VERSION ""

NS_ :

BS_:

BU_: XXX

BO_ 769 TeslaRadarSguInfo: 8 XXX
 SG_ RADC_VerticalMisalignment : 0|8@1+ (1,0) [0|255] "" XXX
 SG_ RADC_SCUTemperature : 8|8@1+ (1,-128) [-128|127] "" XXX
 SG_ RADC_VMA_Plaus : 16|8@1+ (1,0) [0|255] "" XXX
 SG_ RADC_SGU_ITC : 24|8@1+ (1,0) [0|255] "" XXX
 SG_ RADC_HorizontMisalignment : 32|12@1+ (1,0) [0|4096] "" XXX
 SG_ RADC_SensorDirty : 44|1@1+ (1,0) [0|1] "" XXX
 SG_ RADC_HWFail : 45|1@1+ (1,0) [0|1] "" XXX
 SG_ RADC_SGUFail : 46|1@1+ (1,0) [0|1] "" XXX
 SG_ RADC_SGUInfoConsistBit : 47|1@1+ (1,0) [0|1] "" XXX

BO_ 770 TeslaRadarTguInfo: 8 XXX
 SG_ RADC_ACCTargObj1_sguIndex : 0|6@1+ (1,0) [0|63] "" XXX
 SG_ RADC_ACCTargObj2_sguIndex : 6|6@1+ (1,0) [0|63] "" XXX
 SG_ RADC_ACCTargObj3_sguIndex : 12|6@1+ (1,0) [0|63] "" XXX
 SG_ RADC_ACCTargObj4_sguIndex : 18|6@1+ (1,0) [0|63] "" XXX
 SG_ RADC_ACCTargObj5_sguIndex : 24|6@1+ (1,0) [0|63] "" XXX
 SG_ unused30 : 30|1@1+ (1,0) [0|1] "" XXX
 SG_ RADC_TGUInfoConsistBit : 31|1@1+ (1,0) [0|1] "" XXX
 SG_ RADC_ACCTargObj1_dBPower : 32|16@1+ (1,0) [0|65535] "" XXX
 SG_ RADC_ACCTargObj5_dBPower : 48|16@1+ (1,0) [0|65535] "" XXX

BO_ 1281 TeslaRadarAlertMatrix: 8 XXX
 SG_ RADC_a001_ecuInternalPerf : 0|1@1+ (1,0) [0|1] "" XXX
 SG_ RADC_a002_flashPerformance : 1|1@1+ (1,0) [0|1] "" XXX
 SG_ RADC_a003_vBatHigh : 2|1@1+ (1,0) [0|1] "" XXX
 SG_ RADC_a004_adjustmentNotDone : 3|1@1+ (1,0) [0|1] "" XXX
 SG_ RADC_a005_adjustmentReq : 4|1@1+ (1,0) [0|1] "" XXX
 SG_ RADC_a006_adjustmentNotOk : 5|1@1+ (1,0) [0|1] "" XXX
 SG_ RADC_a007_sensorBlinded : 6|1@1+ (1,0) [0|1] "" XXX
 SG_ RADC_a008_plantModeActive : 7|1@1+ (1,0) [0|1] "" XXX
 SG_ RADC_a009_configMismatch : 8|1@1+ (1,0) [0|1] "" XXX
 SG_ RADC_a010_canBusOff : 9|1@1+ (1,0) [0|1] "" XXX
 SG_ RADC_a011_bdyMIA : 10|1@1+ (1,0) [0|1] "" XXX
 SG_ RADC_a012_espMIA : 11|1@1+ (1,0) [0|1] "" XXX
 SG_ RADC_a013_gtwMIA : 12|1@1+ (1,0) [0|1] "" XXX
 SG_ RADC_a014_sccmMIA : 13|1@1+ (1,0) [0|1] "" XXX
 SG_ RADC_a015_adasMIA : 14|1@1+ (1,0) [0|1] "" XXX
 SG_ RADC_a016_bdyInvalidCount : 15|1@1+ (1,0) [0|1] "" XXX
 SG_ RADC_a017_adasInvalidCount : 16|1@1+ (1,0) [0|1] "" XXX
 SG_ RADC_a018_espInvalidCount : 17|1@1+ (1,0) [0|1] "" XXX
 SG_ RADC_a019_sccmInvalidCount : 18|1@1+ (1,0) [0|1] "" XXX
 SG_ RADC_a020_bdyInvalidChkSm : 19|1@1+ (1,0) [0|1] "" XXX
 SG_ RADC_a021_espInvalidChkSm : 20|1@1+ (1,0) [0|1] "" XXX
 SG_ RADC_a022_sccmInvalidChkSm : 21|1@1+ (1,0) [0|1] "" XXX
 SG_ RADC_a023_sccmInvalidChkSm : 22|1@1+ (1,0) [0|1] "" XXX
 SG_ RADC_a024_absValidity : 23|1@1+ (1,0) [0|1] "" XXX
 SG_ RADC_a025_ambTValidity : 24|1@1+ (1,0) [0|1] "" XXX
 SG_ RADC_a026_brakeValidity : 25|1@1+ (1,0) [0|1] "" XXX
 SG_ RADC_a027_CntryCdValidity : 26|1@1+ (1,0) [0|1] "" XXX
 SG_ RADC_a028_espValidity : 27|1@1+ (1,0) [0|1] "" XXX
 SG_ RADC_a029_longAccOffValidity : 28|1@1+ (1,0) [0|1] "" XXX
 SG_ RADC_a030_longAccValidity : 29|1@1+ (1,0) [0|1] "" XXX
 SG_ RADC_a031_odoValidity : 30|1@1+ (1,0) [0|1] "" XXX
 SG_ RADC_a032_gearValidity : 31|1@1+ (1,0) [0|1] "" XXX
 SG_ RADC_a033_steerAngValidity : 32|1@1+ (1,0) [0|1] "" XXX
 SG_ RADC_a034_steerAngSpdValidity : 33|1@1+ (1,0) [0|1] "" XXX
 SG_ RADC_a035_indctrValidity : 34|1@1+ (1,0) [0|1] "" XXX
 SG_ RADC_a036_vehStandStillValidity : 35|1@1+ (1,0) [0|1] "" XXX
 SG_ RADC_a037_vinValidity : 36|1@1+ (1,0) [0|1] "" XXX
 SG_ RADC_a038_whlRotValidity : 37|1@1+ (1,0) [0|1] "" XXX
 SG_ RADC_a039_whlSpdValidity : 38|1@1+ (1,0) [0|1] "" XXX
 SG_ RADC_a040_whlStandStillValidity : 39|1@1+ (1,0) [0|1] "" XXX
 SG_ RADC_a041_wiperValidity : 40|1@1+ (1,0) [0|1] "" XXX
 SG_ RADC_a042_xwdValidity : 41|1@1+ (1,0) [0|1] "" XXX
 SG_ RADC_a043_yawOffValidity : 42|1@1+ (1,0) [0|1] "" XXX
 SG_ RADC_a044_yawValidity : 43|1@1+ (1,0) [0|1] "" XXX
 SG_ RADC_a045_bsdSanity : 44|1@1+ (1,0) [0|1] "" XXX
 SG_ RADC_a046_rctaSanity : 45|1@1+ (1,0) [0|1] "" XXX
 SG_ RADC_a047_lcwSanity : 46|1@1+ (1,0) [0|1] "" XXX
 SG_ RADC_a048_steerAngOffSanity : 47|1@1+ (1,0) [0|1] "" XXX
 SG_ RADC_a049_tireSizeSanity : 48|1@1+ (1,0) [0|1] "" XXX
 SG_ RADC_a050_velocitySanity : 49|1@1+ (1,0) [0|1] "" XXX
 SG_ RADC_a051_yawSanity : 50|1@1+ (1,0) [0|1] "" XXX
 SG_ RADC_a052_radomeHtrInop : 51|1@1+ (1,0) [0|1] "" XXX
 SG_ RADC_a053_espmodValidity : 52|1@1+ (1,0) [0|1] "" XXX
 SG_ RADC_a054_gtwmodValidity : 53|1@1+ (1,0) [0|1] "" XXX
 SG_ RADC_a055_stwmodValidity : 54|1@1+ (1,0) [0|1] "" XXX
 SG_ RADC_a056_bcmodValidity : 55|1@1+ (1,0) [0|1] "" XXX
 SG_ RADC_a057_dimodValidity : 56|1@1+ (1,0) [0|1] "" XXX
 SG_ RADC_a058_opmodValidity : 57|1@1+ (1,0) [0|1] "" XXX
 SG_ RADC_a059_drmiInvalidChkSm : 58|1@1+ (1,0) [0|1] "" XXX
 SG_ RADC_a060_drmiInvalidCount : 59|1@1+ (1,0) [0|1] "" XXX
 SG_ RADC_a061_radPositionMismatch : 60|1@1+ (1,0) [0|1] "" XXX
 SG_ RADC_a062_strRackMismatch : 61|1@1+ (1,0) [0|1] "" XXX
 SG_ unused62 : 62|2@1+ (1,0) [0|3] "" XXX

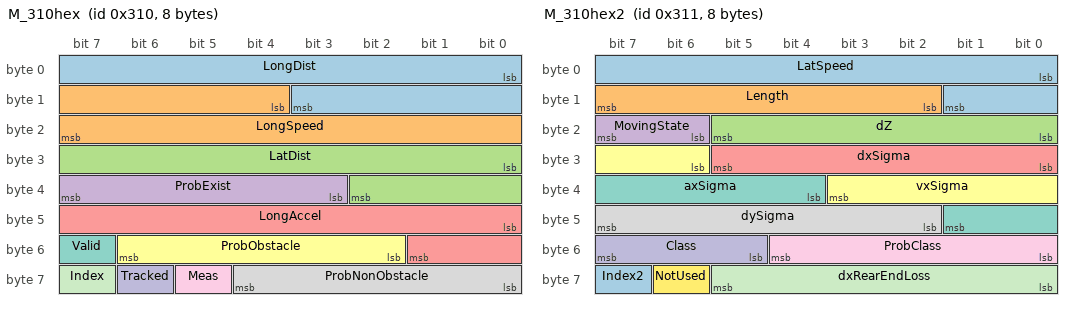
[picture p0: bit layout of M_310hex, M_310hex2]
BO_ 784 M_310hex: 8 XXX
 SG_ LongDist : 0|12@1+ (0.0625,0) [0|255.9] "meters" XXX
 SG_ LongSpeed : 12|12@1+ (0.0625,-128) [-128|128] "meters/sec" XXX
 SG_ LatDist : 24|11@1+ (0.125,-128) [-128|128] "meters" XXX
 SG_ ProbExist : 35|5@1+ (3.125,0) [0|96.875] "%" XXX
 SG_ LongAccel : 40|10@1+ (0.03125,-16) [-16|16] "meters/sec/sec" XXX
 SG_ ProbObstacle : 50|5@1+ (3.125,0) [0|96.875] "%" XXX
 SG_ Valid : 55|1@1+ (1,0) [0|1] "" XXX
 SG_ ProbNonObstacle : 56|5@1+ (3.125,0) [0|96.875] "%" XXX
 SG_ Meas : 61|1@1+ (1,0) [0|1] "" XXX
 SG_ Tracked : 62|1@1+ (1,0) [0|1] "" XXX
 SG_ Index : 63|1@1+ (1,0) [0|1] "" XXX

BO_ 785 M_310hex2: 8 XXX
 SG_ LatSpeed : 0|10@1+ (0.125,-64) [-64|64] "meters/sec" XXX
 SG_ Length : 10|6@1+ (0.125,0) [0|7.875] "m" XXX
 SG_ dZ : 16|6@1+ (0.25,-5) [-5|10.75] "m" XXX
 SG_ MovingState : 22|2@1+ (1,0) [0|3] "" XXX
 SG_ dxSigma : 24|6@1+ (1,0) [0|63] "" XXX
 SG_ vxSigma : 30|6@1+ (1,0) [0|63] "" XXX
 SG_ axSigma : 36|6@1+ (1,0) [0|63] "" XXX
 SG_ dySigma : 42|6@1+ (1,0) [0|63] "" XXX
 SG_ ProbClass : 48|5@1+ (3.125,0) [0|96.875] "%" XXX
 SG_ Class : 53|3@1+ (1,0) [0|7] "" XXX
 SG_ dxRearEndLoss : 56|6@1+ (1,0) [0|63] "" XXX
 SG_ NotUsed : 62|1@1+ (1,0) [0|1] "" XXX
 SG_ Index2 : 63|1@1+ (1,0) [0|1] "" XXX

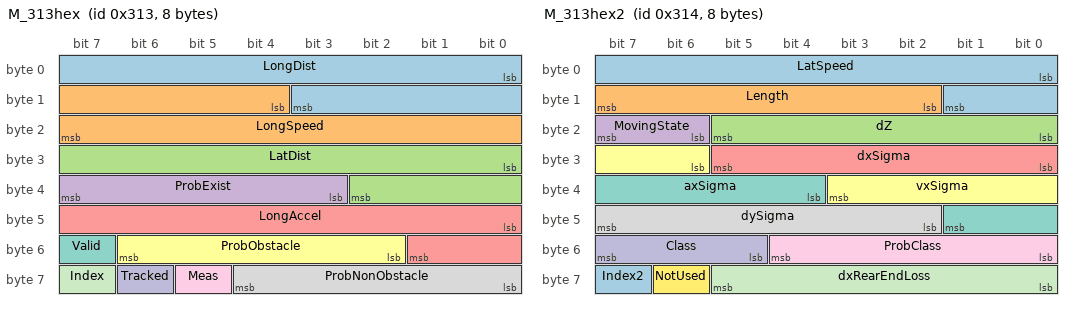
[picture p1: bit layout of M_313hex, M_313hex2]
BO_ 787 M_313hex: 8 XXX
 SG_ LongDist : 0|12@1+ (0.0625,0) [0|255.9] "meters" XXX
 SG_ LongSpeed : 12|12@1+ (0.0625,-128) [-128|128] "meters/sec" XXX
 SG_ LatDist : 24|11@1+ (0.125,-128) [-128|128] "meters" XXX
 SG_ ProbExist : 35|5@1+ (3.125,0) [0|96.875] "%" XXX
 SG_ LongAccel : 40|10@1+ (0.03125,-16) [-16|16] "meters/sec/sec" XXX
 SG_ ProbObstacle : 50|5@1+ (3.125,0) [0|96.875] "%" XXX
 SG_ Valid : 55|1@1+ (1,0) [0|1] "" XXX
 SG_ ProbNonObstacle : 56|5@1+ (3.125,0) [0|96.875] "%" XXX
 SG_ Meas : 61|1@1+ (1,0) [0|1] "" XXX
 SG_ Tracked : 62|1@1+ (1,0) [0|1] "" XXX
 SG_ Index : 63|1@1+ (1,0) [0|1] "" XXX

BO_ 788 M_313hex2: 8 XXX
 SG_ LatSpeed : 0|10@1+ (0.125,-64) [-64|64] "meters/sec" XXX
 SG_ Length : 10|6@1+ (0.125,0) [0|7.875] "m" XXX
 SG_ dZ : 16|6@1+ (0.25,-5) [-5|10.75] "m" XXX
 SG_ MovingState : 22|2@1+ (1,0) [0|3] "" XXX
 SG_ dxSigma : 24|6@1+ (1,0) [0|63] "" XXX
 SG_ vxSigma : 30|6@1+ (1,0) [0|63] "" XXX
 SG_ axSigma : 36|6@1+ (1,0) [0|63] "" XXX
 SG_ dySigma : 42|6@1+ (1,0) [0|63] "" XXX
 SG_ ProbClass : 48|5@1+ (3.125,0) [0|96.875] "%" XXX
 SG_ Class : 53|3@1+ (1,0) [0|7] "" XXX
 SG_ dxRearEndLoss : 56|6@1+ (1,0) [0|63] "" XXX
 SG_ NotUsed : 62|1@1+ (1,0) [0|1] "" XXX
 SG_ Index2 : 63|1@1+ (1,0) [0|1] "" XXX

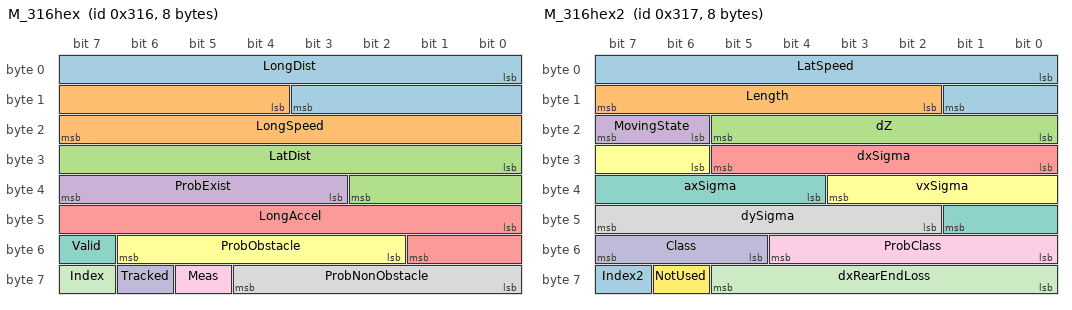
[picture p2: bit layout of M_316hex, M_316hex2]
BO_ 790 M_316hex: 8 XXX
 SG_ LongDist : 0|12@1+ (0.0625,0) [0|255.9] "meters" XXX
 SG_ LongSpeed : 12|12@1+ (0.0625,-128) [-128|128] "meters/sec" XXX
 SG_ LatDist : 24|11@1+ (0.125,-128) [-128|128] "meters" XXX
 SG_ ProbExist : 35|5@1+ (3.125,0) [0|96.875] "%" XXX
 SG_ LongAccel : 40|10@1+ (0.03125,-16) [-16|16] "meters/sec/sec" XXX
 SG_ ProbObstacle : 50|5@1+ (3.125,0) [0|96.875] "%" XXX
 SG_ Valid : 55|1@1+ (1,0) [0|1] "" XXX
 SG_ ProbNonObstacle : 56|5@1+ (3.125,0) [0|96.875] "%" XXX
 SG_ Meas : 61|1@1+ (1,0) [0|1] "" XXX
 SG_ Tracked : 62|1@1+ (1,0) [0|1] "" XXX
 SG_ Index : 63|1@1+ (1,0) [0|1] "" XXX

BO_ 791 M_316hex2: 8 XXX
 SG_ LatSpeed : 0|10@1+ (0.125,-64) [-64|64] "meters/sec" XXX
 SG_ Length : 10|6@1+ (0.125,0) [0|7.875] "m" XXX
 SG_ dZ : 16|6@1+ (0.25,-5) [-5|10.75] "m" XXX
 SG_ MovingState : 22|2@1+ (1,0) [0|3] "" XXX
 SG_ dxSigma : 24|6@1+ (1,0) [0|63] "" XXX
 SG_ vxSigma : 30|6@1+ (1,0) [0|63] "" XXX
 SG_ axSigma : 36|6@1+ (1,0) [0|63] "" XXX
 SG_ dySigma : 42|6@1+ (1,0) [0|63] "" XXX
 SG_ ProbClass : 48|5@1+ (3.125,0) [0|96.875] "%" XXX
 SG_ Class : 53|3@1+ (1,0) [0|7] "" XXX
 SG_ dxRearEndLoss : 56|6@1+ (1,0) [0|63] "" XXX
 SG_ NotUsed : 62|1@1+ (1,0) [0|1] "" XXX
 SG_ Index2 : 63|1@1+ (1,0) [0|1] "" XXX

BO_ 793 M_319hex: 8 XXX
 SG_ LongDist : 0|12@1+ (0.0625,0) [0|255.9] "meters" XXX
 SG_ LongSpeed : 12|12@1+ (0.0625,-128) [-128|128] "meters/sec" XXX
 SG_ LatDist : 24|11@1+ (0.125,-128) [-128|128] "meters" XXX
 SG_ ProbExist : 35|5@1+ (3.125,0) [0|96.875] "%" XXX
 SG_ LongAccel : 40|10@1+ (0.03125,-16) [-16|16] "meters/sec/sec" XXX
 SG_ ProbObstacle : 50|5@1+ (3.125,0) [0|96.875] "%" XXX
 SG_ Valid : 55|1@1+ (1,0) [0|1] "" XXX
 SG_ ProbNonObstacle : 56|5@1+ (3.125,0) [0|96.875] "%" XXX
 SG_ Meas : 61|1@1+ (1,0) [0|1] "" XXX
 SG_ Tracked : 62|1@1+ (1,0) [0|1] "" XXX
 SG_ Index : 63|1@1+ (1,0) [0|1] "" XXX

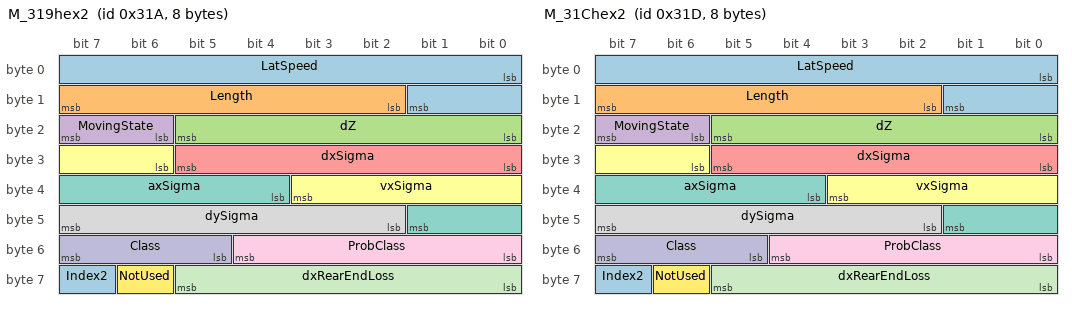
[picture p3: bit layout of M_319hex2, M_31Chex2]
BO_ 794 M_319hex2: 8 XXX
 SG_ LatSpeed : 0|10@1+ (0.125,-64) [-64|64] "meters/sec" XXX
 SG_ Length : 10|6@1+ (0.125,0) [0|7.875] "m" XXX
 SG_ dZ : 16|6@1+ (0.25,-5) [-5|10.75] "m" XXX
 SG_ MovingState : 22|2@1+ (1,0) [0|3] "" XXX
 SG_ dxSigma : 24|6@1+ (1,0) [0|63] "" XXX
 SG_ vxSigma : 30|6@1+ (1,0) [0|63] "" XXX
 SG_ axSigma : 36|6@1+ (1,0) [0|63] "" XXX
 SG_ dySigma : 42|6@1+ (1,0) [0|63] "" XXX
 SG_ ProbClass : 48|5@1+ (3.125,0) [0|96.875] "%" XXX
 SG_ Class : 53|3@1+ (1,0) [0|7] "" XXX
 SG_ dxRearEndLoss : 56|6@1+ (1,0) [0|63] "" XXX
 SG_ NotUsed : 62|1@1+ (1,0) [0|1] "" XXX
 SG_ Index2 : 63|1@1+ (1,0) [0|1] "" XXX

BO_ 796 M_31Chex: 8 XXX
 SG_ LongDist : 0|12@1+ (0.0625,0) [0|255.9] "meters" XXX
 SG_ LongSpeed : 12|12@1+ (0.0625,-128) [-128|128] "meters/sec" XXX
 SG_ LatDist : 24|11@1+ (0.125,-128) [-128|128] "meters" XXX
 SG_ ProbExist : 35|5@1+ (3.125,0) [0|96.875] "%" XXX
 SG_ LongAccel : 40|10@1+ (0.03125,-16) [-16|16] "meters/sec/sec" XXX
 SG_ ProbObstacle : 50|5@1+ (3.125,0) [0|96.875] "%" XXX
 SG_ Valid : 55|1@1+ (1,0) [0|1] "" XXX
 SG_ ProbNonObstacle : 56|5@1+ (3.125,0) [0|96.875] "%" XXX
 SG_ Meas : 61|1@1+ (1,0) [0|1] "" XXX
 SG_ Tracked : 62|1@1+ (1,0) [0|1] "" XXX
 SG_ Index : 63|1@1+ (1,0) [0|1] "" XXX

BO_ 797 M_31Chex2: 8 XXX
 SG_ LatSpeed : 0|10@1+ (0.125,-64) [-64|64] "meters/sec" XXX
 SG_ Length : 10|6@1+ (0.125,0) [0|7.875] "m" XXX
 SG_ dZ : 16|6@1+ (0.25,-5) [-5|10.75] "m" XXX
 SG_ MovingState : 22|2@1+ (1,0) [0|3] "" XXX
 SG_ dxSigma : 24|6@1+ (1,0) [0|63] "" XXX
 SG_ vxSigma : 30|6@1+ (1,0) [0|63] "" XXX
 SG_ axSigma : 36|6@1+ (1,0) [0|63] "" XXX
 SG_ dySigma : 42|6@1+ (1,0) [0|63] "" XXX
 SG_ ProbClass : 48|5@1+ (3.125,0) [0|96.875] "%" XXX
 SG_ Class : 53|3@1+ (1,0) [0|7] "" XXX
 SG_ dxRearEndLoss : 56|6@1+ (1,0) [0|63] "" XXX
 SG_ NotUsed : 62|1@1+ (1,0) [0|1] "" XXX
 SG_ Index2 : 63|1@1+ (1,0) [0|1] "" XXX

BO_ 799 M_31Fhex: 8 XXX
 SG_ LongDist : 0|12@1+ (0.0625,0) [0|255.9] "meters" XXX
 SG_ LongSpeed : 12|12@1+ (0.0625,-128) [-128|128] "meters/sec" XXX
 SG_ LatDist : 24|11@1+ (0.125,-128) [-128|128] "meters" XXX
 SG_ ProbExist : 35|5@1+ (3.125,0) [0|96.875] "%" XXX
 SG_ LongAccel : 40|10@1+ (0.03125,-16) [-16|16] "meters/sec/sec" XXX
 SG_ ProbObstacle : 50|5@1+ (3.125,0) [0|96.875] "%" XXX
 SG_ Valid : 55|1@1+ (1,0) [0|1] "" XXX
 SG_ ProbNonObstacle : 56|5@1+ (3.125,0) [0|96.875] "%" XXX
 SG_ Meas : 61|1@1+ (1,0) [0|1] "" XXX
 SG_ Tracked : 62|1@1+ (1,0) [0|1] "" XXX
 SG_ Index : 63|1@1+ (1,0) [0|1] "" XXX

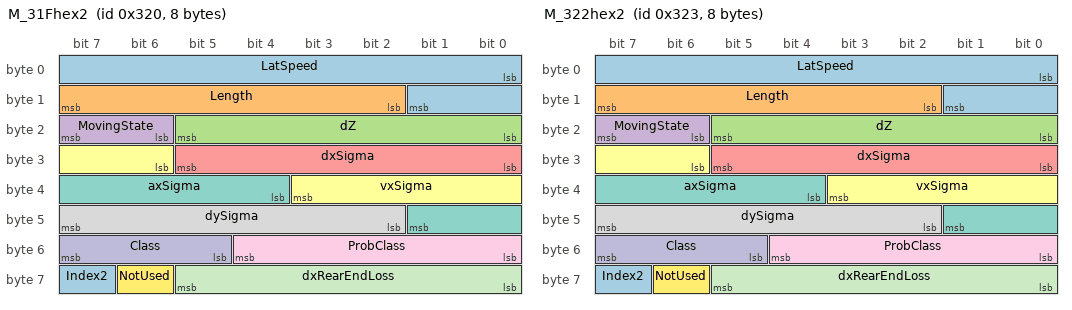
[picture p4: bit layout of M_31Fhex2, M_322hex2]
BO_ 800 M_31Fhex2: 8 XXX
 SG_ LatSpeed : 0|10@1+ (0.125,-64) [-64|64] "meters/sec" XXX
 SG_ Length : 10|6@1+ (0.125,0) [0|7.875] "m" XXX
 SG_ dZ : 16|6@1+ (0.25,-5) [-5|10.75] "m" XXX
 SG_ MovingState : 22|2@1+ (1,0) [0|3] "" XXX
 SG_ dxSigma : 24|6@1+ (1,0) [0|63] "" XXX
 SG_ vxSigma : 30|6@1+ (1,0) [0|63] "" XXX
 SG_ axSigma : 36|6@1+ (1,0) [0|63] "" XXX
 SG_ dySigma : 42|6@1+ (1,0) [0|63] "" XXX
 SG_ ProbClass : 48|5@1+ (3.125,0) [0|96.875] "%" XXX
 SG_ Class : 53|3@1+ (1,0) [0|7] "" XXX
 SG_ dxRearEndLoss : 56|6@1+ (1,0) [0|63] "" XXX
 SG_ NotUsed : 62|1@1+ (1,0) [0|1] "" XXX
 SG_ Index2 : 63|1@1+ (1,0) [0|1] "" XXX

BO_ 802 M_322hex: 8 XXX
 SG_ LongDist : 0|12@1+ (0.0625,0) [0|255.9] "meters" XXX
 SG_ LongSpeed : 12|12@1+ (0.0625,-128) [-128|128] "meters/sec" XXX
 SG_ LatDist : 24|11@1+ (0.125,-128) [-128|128] "meters" XXX
 SG_ ProbExist : 35|5@1+ (3.125,0) [0|96.875] "%" XXX
 SG_ LongAccel : 40|10@1+ (0.03125,-16) [-16|16] "meters/sec/sec" XXX
 SG_ ProbObstacle : 50|5@1+ (3.125,0) [0|96.875] "%" XXX
 SG_ Valid : 55|1@1+ (1,0) [0|1] "" XXX
 SG_ ProbNonObstacle : 56|5@1+ (3.125,0) [0|96.875] "%" XXX
 SG_ Meas : 61|1@1+ (1,0) [0|1] "" XXX
 SG_ Tracked : 62|1@1+ (1,0) [0|1] "" XXX
 SG_ Index : 63|1@1+ (1,0) [0|1] "" XXX

BO_ 803 M_322hex2: 8 XXX
 SG_ LatSpeed : 0|10@1+ (0.125,-64) [-64|64] "meters/sec" XXX
 SG_ Length : 10|6@1+ (0.125,0) [0|7.875] "m" XXX
 SG_ dZ : 16|6@1+ (0.25,-5) [-5|10.75] "m" XXX
 SG_ MovingState : 22|2@1+ (1,0) [0|3] "" XXX
 SG_ dxSigma : 24|6@1+ (1,0) [0|63] "" XXX
 SG_ vxSigma : 30|6@1+ (1,0) [0|63] "" XXX
 SG_ axSigma : 36|6@1+ (1,0) [0|63] "" XXX
 SG_ dySigma : 42|6@1+ (1,0) [0|63] "" XXX
 SG_ ProbClass : 48|5@1+ (3.125,0) [0|96.875] "%" XXX
 SG_ Class : 53|3@1+ (1,0) [0|7] "" XXX
 SG_ dxRearEndLoss : 56|6@1+ (1,0) [0|63] "" XXX
 SG_ NotUsed : 62|1@1+ (1,0) [0|1] "" XXX
 SG_ Index2 : 63|1@1+ (1,0) [0|1] "" XXX

BO_ 805 M_325hex: 8 XXX
 SG_ LongDist : 0|12@1+ (0.0625,0) [0|255.9] "meters" XXX
 SG_ LongSpeed : 12|12@1+ (0.0625,-128) [-128|128] "meters/sec" XXX
 SG_ LatDist : 24|11@1+ (0.125,-128) [-128|128] "meters" XXX
 SG_ ProbExist : 35|5@1+ (3.125,0) [0|96.875] "%" XXX
 SG_ LongAccel : 40|10@1+ (0.03125,-16) [-16|16] "meters/sec/sec" XXX
 SG_ ProbObstacle : 50|5@1+ (3.125,0) [0|96.875] "%" XXX
 SG_ Valid : 55|1@1+ (1,0) [0|1] "" XXX
 SG_ ProbNonObstacle : 56|5@1+ (3.125,0) [0|96.875] "%" XXX
 SG_ Meas : 61|1@1+ (1,0) [0|1] "" XXX
 SG_ Tracked : 62|1@1+ (1,0) [0|1] "" XXX
 SG_ Index : 63|1@1+ (1,0) [0|1] "" XXX

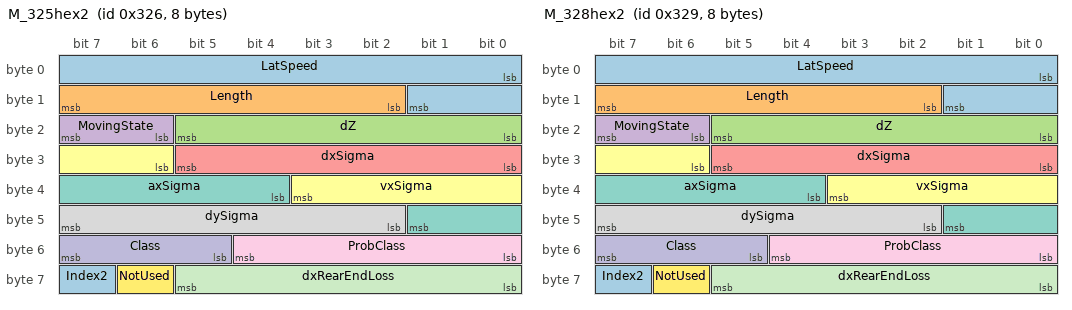
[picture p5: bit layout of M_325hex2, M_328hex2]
BO_ 806 M_325hex2: 8 XXX
 SG_ LatSpeed : 0|10@1+ (0.125,-64) [-64|64] "meters/sec" XXX
 SG_ Length : 10|6@1+ (0.125,0) [0|7.875] "m" XXX
 SG_ dZ : 16|6@1+ (0.25,-5) [-5|10.75] "m" XXX
 SG_ MovingState : 22|2@1+ (1,0) [0|3] "" XXX
 SG_ dxSigma : 24|6@1+ (1,0) [0|63] "" XXX
 SG_ vxSigma : 30|6@1+ (1,0) [0|63] "" XXX
 SG_ axSigma : 36|6@1+ (1,0) [0|63] "" XXX
 SG_ dySigma : 42|6@1+ (1,0) [0|63] "" XXX
 SG_ ProbClass : 48|5@1+ (3.125,0) [0|96.875] "%" XXX
 SG_ Class : 53|3@1+ (1,0) [0|7] "" XXX
 SG_ dxRearEndLoss : 56|6@1+ (1,0) [0|63] "" XXX
 SG_ NotUsed : 62|1@1+ (1,0) [0|1] "" XXX
 SG_ Index2 : 63|1@1+ (1,0) [0|1] "" XXX

BO_ 808 M_328hex: 8 XXX
 SG_ LongDist : 0|12@1+ (0.0625,0) [0|255.9] "meters" XXX
 SG_ LongSpeed : 12|12@1+ (0.0625,-128) [-128|128] "meters/sec" XXX
 SG_ LatDist : 24|11@1+ (0.125,-128) [-128|128] "meters" XXX
 SG_ ProbExist : 35|5@1+ (3.125,0) [0|96.875] "%" XXX
 SG_ LongAccel : 40|10@1+ (0.03125,-16) [-16|16] "meters/sec/sec" XXX
 SG_ ProbObstacle : 50|5@1+ (3.125,0) [0|96.875] "%" XXX
 SG_ Valid : 55|1@1+ (1,0) [0|1] "" XXX
 SG_ ProbNonObstacle : 56|5@1+ (3.125,0) [0|96.875] "%" XXX
 SG_ Meas : 61|1@1+ (1,0) [0|1] "" XXX
 SG_ Tracked : 62|1@1+ (1,0) [0|1] "" XXX
 SG_ Index : 63|1@1+ (1,0) [0|1] "" XXX

BO_ 809 M_328hex2: 8 XXX
 SG_ LatSpeed : 0|10@1+ (0.125,-64) [-64|64] "meters/sec" XXX
 SG_ Length : 10|6@1+ (0.125,0) [0|7.875] "m" XXX
 SG_ dZ : 16|6@1+ (0.25,-5) [-5|10.75] "m" XXX
 SG_ MovingState : 22|2@1+ (1,0) [0|3] "" XXX
 SG_ dxSigma : 24|6@1+ (1,0) [0|63] "" XXX
 SG_ vxSigma : 30|6@1+ (1,0) [0|63] "" XXX
 SG_ axSigma : 36|6@1+ (1,0) [0|63] "" XXX
 SG_ dySigma : 42|6@1+ (1,0) [0|63] "" XXX
 SG_ ProbClass : 48|5@1+ (3.125,0) [0|96.875] "%" XXX
 SG_ Class : 53|3@1+ (1,0) [0|7] "" XXX
 SG_ dxRearEndLoss : 56|6@1+ (1,0) [0|63] "" XXX
 SG_ NotUsed : 62|1@1+ (1,0) [0|1] "" XXX
 SG_ Index2 : 63|1@1+ (1,0) [0|1] "" XXX

BO_ 811 M_32Bhex: 8 XXX
 SG_ LongDist : 0|12@1+ (0.0625,0) [0|255.9] "meters" XXX
 SG_ LongSpeed : 12|12@1+ (0.0625,-128) [-128|128] "meters/sec" XXX
 SG_ LatDist : 24|11@1+ (0.125,-128) [-128|128] "meters" XXX
 SG_ ProbExist : 35|5@1+ (3.125,0) [0|96.875] "%" XXX
 SG_ LongAccel : 40|10@1+ (0.03125,-16) [-16|16] "meters/sec/sec" XXX
 SG_ ProbObstacle : 50|5@1+ (3.125,0) [0|96.875] "%" XXX
 SG_ Valid : 55|1@1+ (1,0) [0|1] "" XXX
 SG_ ProbNonObstacle : 56|5@1+ (3.125,0) [0|96.875] "%" XXX
 SG_ Meas : 61|1@1+ (1,0) [0|1] "" XXX
 SG_ Tracked : 62|1@1+ (1,0) [0|1] "" XXX
 SG_ Index : 63|1@1+ (1,0) [0|1] "" XXX

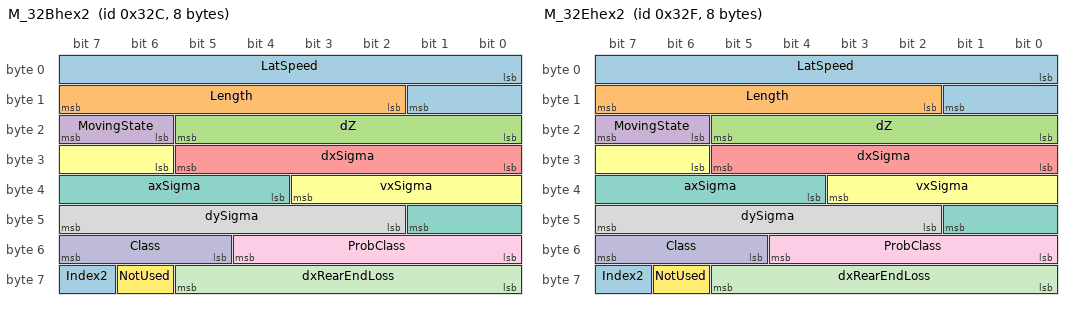
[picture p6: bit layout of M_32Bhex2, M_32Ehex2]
BO_ 812 M_32Bhex2: 8 XXX
 SG_ LatSpeed : 0|10@1+ (0.125,-64) [-64|64] "meters/sec" XXX
 SG_ Length : 10|6@1+ (0.125,0) [0|7.875] "m" XXX
 SG_ dZ : 16|6@1+ (0.25,-5) [-5|10.75] "m" XXX
 SG_ MovingState : 22|2@1+ (1,0) [0|3] "" XXX
 SG_ dxSigma : 24|6@1+ (1,0) [0|63] "" XXX
 SG_ vxSigma : 30|6@1+ (1,0) [0|63] "" XXX
 SG_ axSigma : 36|6@1+ (1,0) [0|63] "" XXX
 SG_ dySigma : 42|6@1+ (1,0) [0|63] "" XXX
 SG_ ProbClass : 48|5@1+ (3.125,0) [0|96.875] "%" XXX
 SG_ Class : 53|3@1+ (1,0) [0|7] "" XXX
 SG_ dxRearEndLoss : 56|6@1+ (1,0) [0|63] "" XXX
 SG_ NotUsed : 62|1@1+ (1,0) [0|1] "" XXX
 SG_ Index2 : 63|1@1+ (1,0) [0|1] "" XXX

BO_ 814 M_32Ehex: 8 XXX
 SG_ LongDist : 0|12@1+ (0.0625,0) [0|255.9] "meters" XXX
 SG_ LongSpeed : 12|12@1+ (0.0625,-128) [-128|128] "meters/sec" XXX
 SG_ LatDist : 24|11@1+ (0.125,-128) [-128|128] "meters" XXX
 SG_ ProbExist : 35|5@1+ (3.125,0) [0|96.875] "%" XXX
 SG_ LongAccel : 40|10@1+ (0.03125,-16) [-16|16] "meters/sec/sec" XXX
 SG_ ProbObstacle : 50|5@1+ (3.125,0) [0|96.875] "%" XXX
 SG_ Valid : 55|1@1+ (1,0) [0|1] "" XXX
 SG_ ProbNonObstacle : 56|5@1+ (3.125,0) [0|96.875] "%" XXX
 SG_ Meas : 61|1@1+ (1,0) [0|1] "" XXX
 SG_ Tracked : 62|1@1+ (1,0) [0|1] "" XXX
 SG_ Index : 63|1@1+ (1,0) [0|1] "" XXX

BO_ 815 M_32Ehex2: 8 XXX
 SG_ LatSpeed : 0|10@1+ (0.125,-64) [-64|64] "meters/sec" XXX
 SG_ Length : 10|6@1+ (0.125,0) [0|7.875] "m" XXX
 SG_ dZ : 16|6@1+ (0.25,-5) [-5|10.75] "m" XXX
 SG_ MovingState : 22|2@1+ (1,0) [0|3] "" XXX
 SG_ dxSigma : 24|6@1+ (1,0) [0|63] "" XXX
 SG_ vxSigma : 30|6@1+ (1,0) [0|63] "" XXX
 SG_ axSigma : 36|6@1+ (1,0) [0|63] "" XXX
 SG_ dySigma : 42|6@1+ (1,0) [0|63] "" XXX
 SG_ ProbClass : 48|5@1+ (3.125,0) [0|96.875] "%" XXX
 SG_ Class : 53|3@1+ (1,0) [0|7] "" XXX
 SG_ dxRearEndLoss : 56|6@1+ (1,0) [0|63] "" XXX
 SG_ NotUsed : 62|1@1+ (1,0) [0|1] "" XXX
 SG_ Index2 : 63|1@1+ (1,0) [0|1] "" XXX

BO_ 817 M_331hex: 8 XXX
 SG_ LongDist : 0|12@1+ (0.0625,0) [0|255.9] "meters" XXX
 SG_ LongSpeed : 12|12@1+ (0.0625,-128) [-128|128] "meters/sec" XXX
 SG_ LatDist : 24|11@1+ (0.125,-128) [-128|128] "meters" XXX
 SG_ ProbExist : 35|5@1+ (3.125,0) [0|96.875] "%" XXX
 SG_ LongAccel : 40|10@1+ (0.03125,-16) [-16|16] "meters/sec/sec" XXX
 SG_ ProbObstacle : 50|5@1+ (3.125,0) [0|96.875] "%" XXX
 SG_ Valid : 55|1@1+ (1,0) [0|1] "" XXX
 SG_ ProbNonObstacle : 56|5@1+ (3.125,0) [0|96.875] "%" XXX
 SG_ Meas : 61|1@1+ (1,0) [0|1] "" XXX
 SG_ Tracked : 62|1@1+ (1,0) [0|1] "" XXX
 SG_ Index : 63|1@1+ (1,0) [0|1] "" XXX

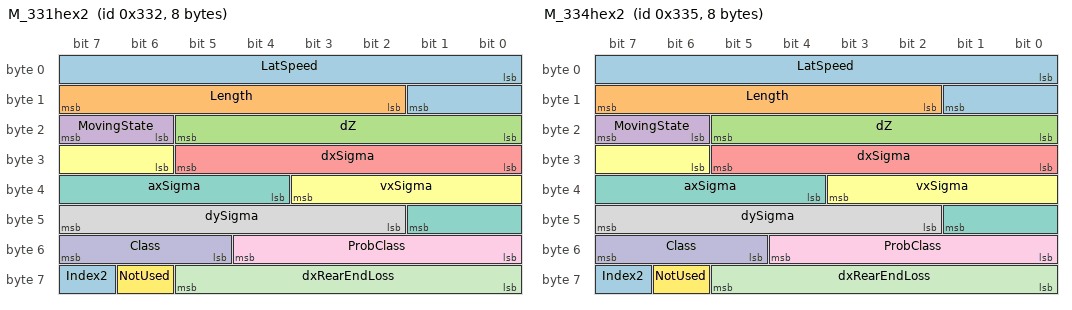
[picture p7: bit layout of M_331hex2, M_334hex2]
BO_ 818 M_331hex2: 8 XXX
 SG_ LatSpeed : 0|10@1+ (0.125,-64) [-64|64] "meters/sec" XXX
 SG_ Length : 10|6@1+ (0.125,0) [0|7.875] "m" XXX
 SG_ dZ : 16|6@1+ (0.25,-5) [-5|10.75] "m" XXX
 SG_ MovingState : 22|2@1+ (1,0) [0|3] "" XXX
 SG_ dxSigma : 24|6@1+ (1,0) [0|63] "" XXX
 SG_ vxSigma : 30|6@1+ (1,0) [0|63] "" XXX
 SG_ axSigma : 36|6@1+ (1,0) [0|63] "" XXX
 SG_ dySigma : 42|6@1+ (1,0) [0|63] "" XXX
 SG_ ProbClass : 48|5@1+ (3.125,0) [0|96.875] "%" XXX
 SG_ Class : 53|3@1+ (1,0) [0|7] "" XXX
 SG_ dxRearEndLoss : 56|6@1+ (1,0) [0|63] "" XXX
 SG_ NotUsed : 62|1@1+ (1,0) [0|1] "" XXX
 SG_ Index2 : 63|1@1+ (1,0) [0|1] "" XXX

BO_ 820 M_334hex: 8 XXX
 SG_ LongDist : 0|12@1+ (0.0625,0) [0|255.9] "meters" XXX
 SG_ LongSpeed : 12|12@1+ (0.0625,-128) [-128|128] "meters/sec" XXX
 SG_ LatDist : 24|11@1+ (0.125,-128) [-128|128] "meters" XXX
 SG_ ProbExist : 35|5@1+ (3.125,0) [0|96.875] "%" XXX
 SG_ LongAccel : 40|10@1+ (0.03125,-16) [-16|16] "meters/sec/sec" XXX
 SG_ ProbObstacle : 50|5@1+ (3.125,0) [0|96.875] "%" XXX
 SG_ Valid : 55|1@1+ (1,0) [0|1] "" XXX
 SG_ ProbNonObstacle : 56|5@1+ (3.125,0) [0|96.875] "%" XXX
 SG_ Meas : 61|1@1+ (1,0) [0|1] "" XXX
 SG_ Tracked : 62|1@1+ (1,0) [0|1] "" XXX
 SG_ Index : 63|1@1+ (1,0) [0|1] "" XXX

BO_ 821 M_334hex2: 8 XXX
 SG_ LatSpeed : 0|10@1+ (0.125,-64) [-64|64] "meters/sec" XXX
 SG_ Length : 10|6@1+ (0.125,0) [0|7.875] "m" XXX
 SG_ dZ : 16|6@1+ (0.25,-5) [-5|10.75] "m" XXX
 SG_ MovingState : 22|2@1+ (1,0) [0|3] "" XXX
 SG_ dxSigma : 24|6@1+ (1,0) [0|63] "" XXX
 SG_ vxSigma : 30|6@1+ (1,0) [0|63] "" XXX
 SG_ axSigma : 36|6@1+ (1,0) [0|63] "" XXX
 SG_ dySigma : 42|6@1+ (1,0) [0|63] "" XXX
 SG_ ProbClass : 48|5@1+ (3.125,0) [0|96.875] "%" XXX
 SG_ Class : 53|3@1+ (1,0) [0|7] "" XXX
 SG_ dxRearEndLoss : 56|6@1+ (1,0) [0|63] "" XXX
 SG_ NotUsed : 62|1@1+ (1,0) [0|1] "" XXX
 SG_ Index2 : 63|1@1+ (1,0) [0|1] "" XXX

BO_ 823 M_337hex: 8 XXX
 SG_ LongDist : 0|12@1+ (0.0625,0) [0|255.9] "meters" XXX
 SG_ LongSpeed : 12|12@1+ (0.0625,-128) [-128|128] "meters/sec" XXX
 SG_ LatDist : 24|11@1+ (0.125,-128) [-128|128] "meters" XXX
 SG_ ProbExist : 35|5@1+ (3.125,0) [0|96.875] "%" XXX
 SG_ LongAccel : 40|10@1+ (0.03125,-16) [-16|16] "meters/sec/sec" XXX
 SG_ ProbObstacle : 50|5@1+ (3.125,0) [0|96.875] "%" XXX
 SG_ Valid : 55|1@1+ (1,0) [0|1] "" XXX
 SG_ ProbNonObstacle : 56|5@1+ (3.125,0) [0|96.875] "%" XXX
 SG_ Meas : 61|1@1+ (1,0) [0|1] "" XXX
 SG_ Tracked : 62|1@1+ (1,0) [0|1] "" XXX
 SG_ Index : 63|1@1+ (1,0) [0|1] "" XXX

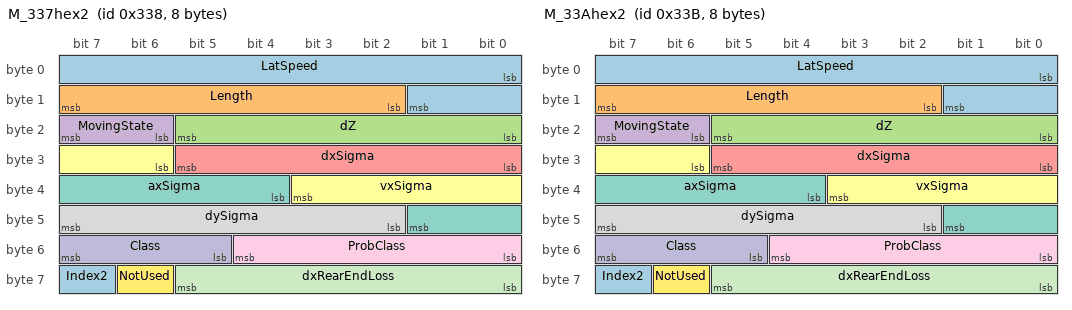
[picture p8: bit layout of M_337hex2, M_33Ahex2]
BO_ 824 M_337hex2: 8 XXX
 SG_ LatSpeed : 0|10@1+ (0.125,-64) [-64|64] "meters/sec" XXX
 SG_ Length : 10|6@1+ (0.125,0) [0|7.875] "m" XXX
 SG_ dZ : 16|6@1+ (0.25,-5) [-5|10.75] "m" XXX
 SG_ MovingState : 22|2@1+ (1,0) [0|3] "" XXX
 SG_ dxSigma : 24|6@1+ (1,0) [0|63] "" XXX
 SG_ vxSigma : 30|6@1+ (1,0) [0|63] "" XXX
 SG_ axSigma : 36|6@1+ (1,0) [0|63] "" XXX
 SG_ dySigma : 42|6@1+ (1,0) [0|63] "" XXX
 SG_ ProbClass : 48|5@1+ (3.125,0) [0|96.875] "%" XXX
 SG_ Class : 53|3@1+ (1,0) [0|7] "" XXX
 SG_ dxRearEndLoss : 56|6@1+ (1,0) [0|63] "" XXX
 SG_ NotUsed : 62|1@1+ (1,0) [0|1] "" XXX
 SG_ Index2 : 63|1@1+ (1,0) [0|1] "" XXX

BO_ 826 M_33Ahex: 8 XXX
 SG_ LongDist : 0|12@1+ (0.0625,0) [0|255.9] "meters" XXX
 SG_ LongSpeed : 12|12@1+ (0.0625,-128) [-128|128] "meters/sec" XXX
 SG_ LatDist : 24|11@1+ (0.125,-128) [-128|128] "meters" XXX
 SG_ ProbExist : 35|5@1+ (3.125,0) [0|96.875] "%" XXX
 SG_ LongAccel : 40|10@1+ (0.03125,-16) [-16|16] "meters/sec/sec" XXX
 SG_ ProbObstacle : 50|5@1+ (3.125,0) [0|96.875] "%" XXX
 SG_ Valid : 55|1@1+ (1,0) [0|1] "" XXX
 SG_ ProbNonObstacle : 56|5@1+ (3.125,0) [0|96.875] "%" XXX
 SG_ Meas : 61|1@1+ (1,0) [0|1] "" XXX
 SG_ Tracked : 62|1@1+ (1,0) [0|1] "" XXX
 SG_ Index : 63|1@1+ (1,0) [0|1] "" XXX

BO_ 827 M_33Ahex2: 8 XXX
 SG_ LatSpeed : 0|10@1+ (0.125,-64) [-64|64] "meters/sec" XXX
 SG_ Length : 10|6@1+ (0.125,0) [0|7.875] "m" XXX
 SG_ dZ : 16|6@1+ (0.25,-5) [-5|10.75] "m" XXX
 SG_ MovingState : 22|2@1+ (1,0) [0|3] "" XXX
 SG_ dxSigma : 24|6@1+ (1,0) [0|63] "" XXX
 SG_ vxSigma : 30|6@1+ (1,0) [0|63] "" XXX
 SG_ axSigma : 36|6@1+ (1,0) [0|63] "" XXX
 SG_ dySigma : 42|6@1+ (1,0) [0|63] "" XXX
 SG_ ProbClass : 48|5@1+ (3.125,0) [0|96.875] "%" XXX
 SG_ Class : 53|3@1+ (1,0) [0|7] "" XXX
 SG_ dxRearEndLoss : 56|6@1+ (1,0) [0|63] "" XXX
 SG_ NotUsed : 62|1@1+ (1,0) [0|1] "" XXX
 SG_ Index2 : 63|1@1+ (1,0) [0|1] "" XXX

BO_ 829 M_33Dhex: 8 XXX
 SG_ LongDist : 0|12@1+ (0.0625,0) [0|255.9] "meters" XXX
 SG_ LongSpeed : 12|12@1+ (0.0625,-128) [-128|128] "meters/sec" XXX
 SG_ LatDist : 24|11@1+ (0.125,-128) [-128|128] "meters" XXX
 SG_ ProbExist : 35|5@1+ (3.125,0) [0|96.875] "%" XXX
 SG_ LongAccel : 40|10@1+ (0.03125,-16) [-16|16] "meters/sec/sec" XXX
 SG_ ProbObstacle : 50|5@1+ (3.125,0) [0|96.875] "%" XXX
 SG_ Valid : 55|1@1+ (1,0) [0|1] "" XXX
 SG_ ProbNonObstacle : 56|5@1+ (3.125,0) [0|96.875] "%" XXX
 SG_ Meas : 61|1@1+ (1,0) [0|1] "" XXX
 SG_ Tracked : 62|1@1+ (1,0) [0|1] "" XXX
 SG_ Index : 63|1@1+ (1,0) [0|1] "" XXX

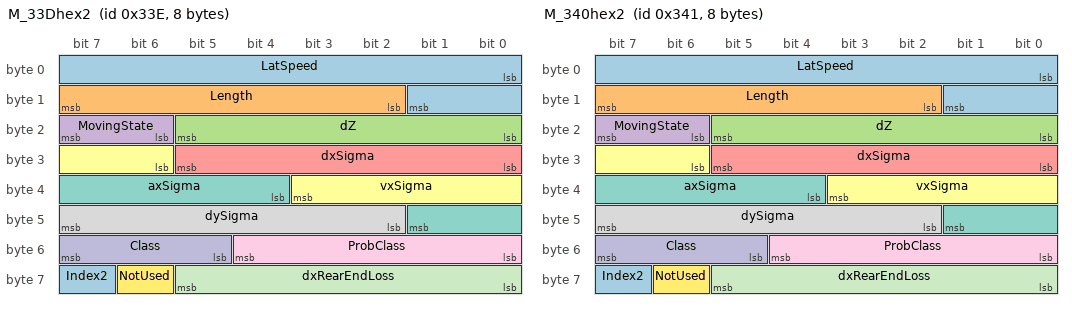
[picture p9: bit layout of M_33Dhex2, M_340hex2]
BO_ 830 M_33Dhex2: 8 XXX
 SG_ LatSpeed : 0|10@1+ (0.125,-64) [-64|64] "meters/sec" XXX
 SG_ Length : 10|6@1+ (0.125,0) [0|7.875] "m" XXX
 SG_ dZ : 16|6@1+ (0.25,-5) [-5|10.75] "m" XXX
 SG_ MovingState : 22|2@1+ (1,0) [0|3] "" XXX
 SG_ dxSigma : 24|6@1+ (1,0) [0|63] "" XXX
 SG_ vxSigma : 30|6@1+ (1,0) [0|63] "" XXX
 SG_ axSigma : 36|6@1+ (1,0) [0|63] "" XXX
 SG_ dySigma : 42|6@1+ (1,0) [0|63] "" XXX
 SG_ ProbClass : 48|5@1+ (3.125,0) [0|96.875] "%" XXX
 SG_ Class : 53|3@1+ (1,0) [0|7] "" XXX
 SG_ dxRearEndLoss : 56|6@1+ (1,0) [0|63] "" XXX
 SG_ NotUsed : 62|1@1+ (1,0) [0|1] "" XXX
 SG_ Index2 : 63|1@1+ (1,0) [0|1] "" XXX

BO_ 832 M_340hex: 8 XXX
 SG_ LongDist : 0|12@1+ (0.0625,0) [0|255.9] "meters" XXX
 SG_ LongSpeed : 12|12@1+ (0.0625,-128) [-128|128] "meters/sec" XXX
 SG_ LatDist : 24|11@1+ (0.125,-128) [-128|128] "meters" XXX
 SG_ ProbExist : 35|5@1+ (3.125,0) [0|96.875] "%" XXX
 SG_ LongAccel : 40|10@1+ (0.03125,-16) [-16|16] "meters/sec/sec" XXX
 SG_ ProbObstacle : 50|5@1+ (3.125,0) [0|96.875] "%" XXX
 SG_ Valid : 55|1@1+ (1,0) [0|1] "" XXX
 SG_ ProbNonObstacle : 56|5@1+ (3.125,0) [0|96.875] "%" XXX
 SG_ Meas : 61|1@1+ (1,0) [0|1] "" XXX
 SG_ Tracked : 62|1@1+ (1,0) [0|1] "" XXX
 SG_ Index : 63|1@1+ (1,0) [0|1] "" XXX

BO_ 833 M_340hex2: 8 XXX
 SG_ LatSpeed : 0|10@1+ (0.125,-64) [-64|64] "meters/sec" XXX
 SG_ Length : 10|6@1+ (0.125,0) [0|7.875] "m" XXX
 SG_ dZ : 16|6@1+ (0.25,-5) [-5|10.75] "m" XXX
 SG_ MovingState : 22|2@1+ (1,0) [0|3] "" XXX
 SG_ dxSigma : 24|6@1+ (1,0) [0|63] "" XXX
 SG_ vxSigma : 30|6@1+ (1,0) [0|63] "" XXX
 SG_ axSigma : 36|6@1+ (1,0) [0|63] "" XXX
 SG_ dySigma : 42|6@1+ (1,0) [0|63] "" XXX
 SG_ ProbClass : 48|5@1+ (3.125,0) [0|96.875] "%" XXX
 SG_ Class : 53|3@1+ (1,0) [0|7] "" XXX
 SG_ dxRearEndLoss : 56|6@1+ (1,0) [0|63] "" XXX
 SG_ NotUsed : 62|1@1+ (1,0) [0|1] "" XXX
 SG_ Index2 : 63|1@1+ (1,0) [0|1] "" XXX

BO_ 835 M_343hex: 8 XXX
 SG_ LongDist : 0|12@1+ (0.0625,0) [0|255.9] "meters" XXX
 SG_ LongSpeed : 12|12@1+ (0.0625,-128) [-128|128] "meters/sec" XXX
 SG_ LatDist : 24|11@1+ (0.125,-128) [-128|128] "meters" XXX
 SG_ ProbExist : 35|5@1+ (3.125,0) [0|96.875] "%" XXX
 SG_ LongAccel : 40|10@1+ (0.03125,-16) [-16|16] "meters/sec/sec" XXX
 SG_ ProbObstacle : 50|5@1+ (3.125,0) [0|96.875] "%" XXX
 SG_ Valid : 55|1@1+ (1,0) [0|1] "" XXX
 SG_ ProbNonObstacle : 56|5@1+ (3.125,0) [0|96.875] "%" XXX
 SG_ Meas : 61|1@1+ (1,0) [0|1] "" XXX
 SG_ Tracked : 62|1@1+ (1,0) [0|1] "" XXX
 SG_ Index : 63|1@1+ (1,0) [0|1] "" XXX

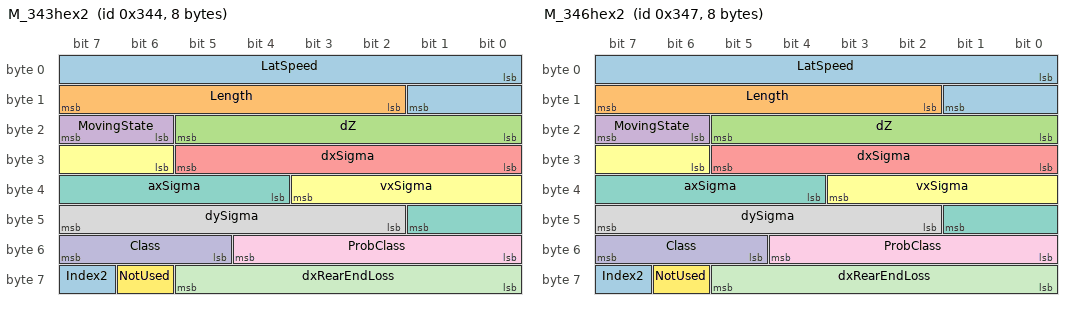
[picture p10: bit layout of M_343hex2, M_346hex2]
BO_ 836 M_343hex2: 8 XXX
 SG_ LatSpeed : 0|10@1+ (0.125,-64) [-64|64] "meters/sec" XXX
 SG_ Length : 10|6@1+ (0.125,0) [0|7.875] "m" XXX
 SG_ dZ : 16|6@1+ (0.25,-5) [-5|10.75] "m" XXX
 SG_ MovingState : 22|2@1+ (1,0) [0|3] "" XXX
 SG_ dxSigma : 24|6@1+ (1,0) [0|63] "" XXX
 SG_ vxSigma : 30|6@1+ (1,0) [0|63] "" XXX
 SG_ axSigma : 36|6@1+ (1,0) [0|63] "" XXX
 SG_ dySigma : 42|6@1+ (1,0) [0|63] "" XXX
 SG_ ProbClass : 48|5@1+ (3.125,0) [0|96.875] "%" XXX
 SG_ Class : 53|3@1+ (1,0) [0|7] "" XXX
 SG_ dxRearEndLoss : 56|6@1+ (1,0) [0|63] "" XXX
 SG_ NotUsed : 62|1@1+ (1,0) [0|1] "" XXX
 SG_ Index2 : 63|1@1+ (1,0) [0|1] "" XXX

BO_ 838 M_346hex: 8 XXX
 SG_ LongDist : 0|12@1+ (0.0625,0) [0|255.9] "meters" XXX
 SG_ LongSpeed : 12|12@1+ (0.0625,-128) [-128|128] "meters/sec" XXX
 SG_ LatDist : 24|11@1+ (0.125,-128) [-128|128] "meters" XXX
 SG_ ProbExist : 35|5@1+ (3.125,0) [0|96.875] "%" XXX
 SG_ LongAccel : 40|10@1+ (0.03125,-16) [-16|16] "meters/sec/sec" XXX
 SG_ ProbObstacle : 50|5@1+ (3.125,0) [0|96.875] "%" XXX
 SG_ Valid : 55|1@1+ (1,0) [0|1] "" XXX
 SG_ ProbNonObstacle : 56|5@1+ (3.125,0) [0|96.875] "%" XXX
 SG_ Meas : 61|1@1+ (1,0) [0|1] "" XXX
 SG_ Tracked : 62|1@1+ (1,0) [0|1] "" XXX
 SG_ Index : 63|1@1+ (1,0) [0|1] "" XXX

BO_ 839 M_346hex2: 8 XXX
 SG_ LatSpeed : 0|10@1+ (0.125,-64) [-64|64] "meters/sec" XXX
 SG_ Length : 10|6@1+ (0.125,0) [0|7.875] "m" XXX
 SG_ dZ : 16|6@1+ (0.25,-5) [-5|10.75] "m" XXX
 SG_ MovingState : 22|2@1+ (1,0) [0|3] "" XXX
 SG_ dxSigma : 24|6@1+ (1,0) [0|63] "" XXX
 SG_ vxSigma : 30|6@1+ (1,0) [0|63] "" XXX
 SG_ axSigma : 36|6@1+ (1,0) [0|63] "" XXX
 SG_ dySigma : 42|6@1+ (1,0) [0|63] "" XXX
 SG_ ProbClass : 48|5@1+ (3.125,0) [0|96.875] "%" XXX
 SG_ Class : 53|3@1+ (1,0) [0|7] "" XXX
 SG_ dxRearEndLoss : 56|6@1+ (1,0) [0|63] "" XXX
 SG_ NotUsed : 62|1@1+ (1,0) [0|1] "" XXX
 SG_ Index2 : 63|1@1+ (1,0) [0|1] "" XXX

BO_ 841 M_349hex: 8 XXX
 SG_ LongDist : 0|12@1+ (0.0625,0) [0|255.9] "meters" XXX
 SG_ LongSpeed : 12|12@1+ (0.0625,-128) [-128|128] "meters/sec" XXX
 SG_ LatDist : 24|11@1+ (0.125,-128) [-128|128] "meters" XXX
 SG_ ProbExist : 35|5@1+ (3.125,0) [0|96.875] "%" XXX
 SG_ LongAccel : 40|10@1+ (0.03125,-16) [-16|16] "meters/sec/sec" XXX
 SG_ ProbObstacle : 50|5@1+ (3.125,0) [0|96.875] "%" XXX
 SG_ Valid : 55|1@1+ (1,0) [0|1] "" XXX
 SG_ ProbNonObstacle : 56|5@1+ (3.125,0) [0|96.875] "%" XXX
 SG_ Meas : 61|1@1+ (1,0) [0|1] "" XXX
 SG_ Tracked : 62|1@1+ (1,0) [0|1] "" XXX
 SG_ Index : 63|1@1+ (1,0) [0|1] "" XXX

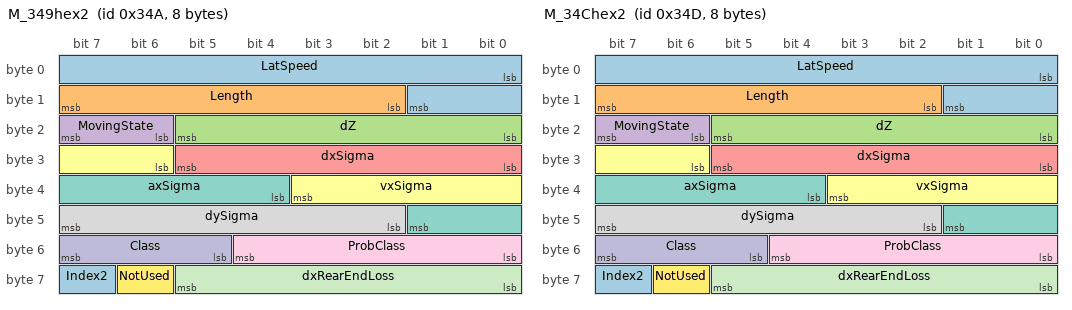
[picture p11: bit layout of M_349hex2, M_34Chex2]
BO_ 842 M_349hex2: 8 XXX
 SG_ LatSpeed : 0|10@1+ (0.125,-64) [-64|64] "meters/sec" XXX
 SG_ Length : 10|6@1+ (0.125,0) [0|7.875] "m" XXX
 SG_ dZ : 16|6@1+ (0.25,-5) [-5|10.75] "m" XXX
 SG_ MovingState : 22|2@1+ (1,0) [0|3] "" XXX
 SG_ dxSigma : 24|6@1+ (1,0) [0|63] "" XXX
 SG_ vxSigma : 30|6@1+ (1,0) [0|63] "" XXX
 SG_ axSigma : 36|6@1+ (1,0) [0|63] "" XXX
 SG_ dySigma : 42|6@1+ (1,0) [0|63] "" XXX
 SG_ ProbClass : 48|5@1+ (3.125,0) [0|96.875] "%" XXX
 SG_ Class : 53|3@1+ (1,0) [0|7] "" XXX
 SG_ dxRearEndLoss : 56|6@1+ (1,0) [0|63] "" XXX
 SG_ NotUsed : 62|1@1+ (1,0) [0|1] "" XXX
 SG_ Index2 : 63|1@1+ (1,0) [0|1] "" XXX

BO_ 844 M_34Chex: 8 XXX
 SG_ LongDist : 0|12@1+ (0.0625,0) [0|255.9] "meters" XXX
 SG_ LongSpeed : 12|12@1+ (0.0625,-128) [-128|128] "meters/sec" XXX
 SG_ LatDist : 24|11@1+ (0.125,-128) [-128|128] "meters" XXX
 SG_ ProbExist : 35|5@1+ (3.125,0) [0|96.875] "%" XXX
 SG_ LongAccel : 40|10@1+ (0.03125,-16) [-16|16] "meters/sec/sec" XXX
 SG_ ProbObstacle : 50|5@1+ (3.125,0) [0|96.875] "%" XXX
 SG_ Valid : 55|1@1+ (1,0) [0|1] "" XXX
 SG_ ProbNonObstacle : 56|5@1+ (3.125,0) [0|96.875] "%" XXX
 SG_ Meas : 61|1@1+ (1,0) [0|1] "" XXX
 SG_ Tracked : 62|1@1+ (1,0) [0|1] "" XXX
 SG_ Index : 63|1@1+ (1,0) [0|1] "" XXX

BO_ 845 M_34Chex2: 8 XXX
 SG_ LatSpeed : 0|10@1+ (0.125,-64) [-64|64] "meters/sec" XXX
 SG_ Length : 10|6@1+ (0.125,0) [0|7.875] "m" XXX
 SG_ dZ : 16|6@1+ (0.25,-5) [-5|10.75] "m" XXX
 SG_ MovingState : 22|2@1+ (1,0) [0|3] "" XXX
 SG_ dxSigma : 24|6@1+ (1,0) [0|63] "" XXX
 SG_ vxSigma : 30|6@1+ (1,0) [0|63] "" XXX
 SG_ axSigma : 36|6@1+ (1,0) [0|63] "" XXX
 SG_ dySigma : 42|6@1+ (1,0) [0|63] "" XXX
 SG_ ProbClass : 48|5@1+ (3.125,0) [0|96.875] "%" XXX
 SG_ Class : 53|3@1+ (1,0) [0|7] "" XXX
 SG_ dxRearEndLoss : 56|6@1+ (1,0) [0|63] "" XXX
 SG_ NotUsed : 62|1@1+ (1,0) [0|1] "" XXX
 SG_ Index2 : 63|1@1+ (1,0) [0|1] "" XXX

BO_ 847 M_34Fhex: 8 XXX
 SG_ LongDist : 0|12@1+ (0.0625,0) [0|255.9] "meters" XXX
 SG_ LongSpeed : 12|12@1+ (0.0625,-128) [-128|128] "meters/sec" XXX
 SG_ LatDist : 24|11@1+ (0.125,-128) [-128|128] "meters" XXX
 SG_ ProbExist : 35|5@1+ (3.125,0) [0|96.875] "%" XXX
 SG_ LongAccel : 40|10@1+ (0.03125,-16) [-16|16] "meters/sec/sec" XXX
 SG_ ProbObstacle : 50|5@1+ (3.125,0) [0|96.875] "%" XXX
 SG_ Valid : 55|1@1+ (1,0) [0|1] "" XXX
 SG_ ProbNonObstacle : 56|5@1+ (3.125,0) [0|96.875] "%" XXX
 SG_ Meas : 61|1@1+ (1,0) [0|1] "" XXX
 SG_ Tracked : 62|1@1+ (1,0) [0|1] "" XXX
 SG_ Index : 63|1@1+ (1,0) [0|1] "" XXX

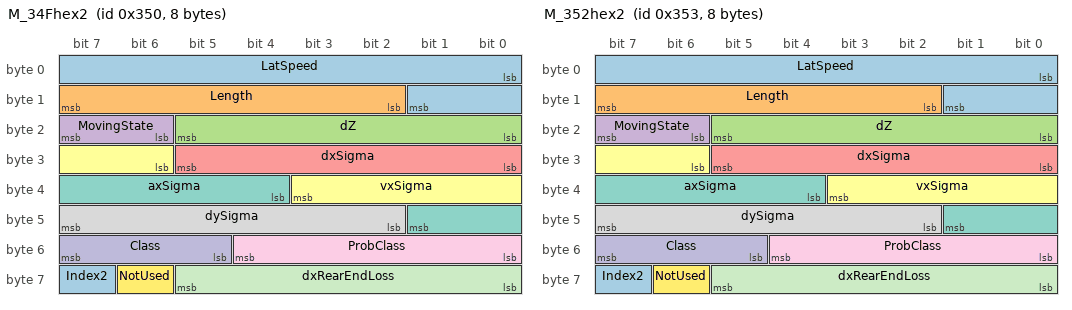
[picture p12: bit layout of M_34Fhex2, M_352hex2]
BO_ 848 M_34Fhex2: 8 XXX
 SG_ LatSpeed : 0|10@1+ (0.125,-64) [-64|64] "meters/sec" XXX
 SG_ Length : 10|6@1+ (0.125,0) [0|7.875] "m" XXX
 SG_ dZ : 16|6@1+ (0.25,-5) [-5|10.75] "m" XXX
 SG_ MovingState : 22|2@1+ (1,0) [0|3] "" XXX
 SG_ dxSigma : 24|6@1+ (1,0) [0|63] "" XXX
 SG_ vxSigma : 30|6@1+ (1,0) [0|63] "" XXX
 SG_ axSigma : 36|6@1+ (1,0) [0|63] "" XXX
 SG_ dySigma : 42|6@1+ (1,0) [0|63] "" XXX
 SG_ ProbClass : 48|5@1+ (3.125,0) [0|96.875] "%" XXX
 SG_ Class : 53|3@1+ (1,0) [0|7] "" XXX
 SG_ dxRearEndLoss : 56|6@1+ (1,0) [0|63] "" XXX
 SG_ NotUsed : 62|1@1+ (1,0) [0|1] "" XXX
 SG_ Index2 : 63|1@1+ (1,0) [0|1] "" XXX

BO_ 850 M_352hex: 8 XXX
 SG_ LongDist : 0|12@1+ (0.0625,0) [0|255.9] "meters" XXX
 SG_ LongSpeed : 12|12@1+ (0.0625,-128) [-128|128] "meters/sec" XXX
 SG_ LatDist : 24|11@1+ (0.125,-128) [-128|128] "meters" XXX
 SG_ ProbExist : 35|5@1+ (3.125,0) [0|96.875] "%" XXX
 SG_ LongAccel : 40|10@1+ (0.03125,-16) [-16|16] "meters/sec/sec" XXX
 SG_ ProbObstacle : 50|5@1+ (3.125,0) [0|96.875] "%" XXX
 SG_ Valid : 55|1@1+ (1,0) [0|1] "" XXX
 SG_ ProbNonObstacle : 56|5@1+ (3.125,0) [0|96.875] "%" XXX
 SG_ Meas : 61|1@1+ (1,0) [0|1] "" XXX
 SG_ Tracked : 62|1@1+ (1,0) [0|1] "" XXX
 SG_ Index : 63|1@1+ (1,0) [0|1] "" XXX

BO_ 851 M_352hex2: 8 XXX
 SG_ LatSpeed : 0|10@1+ (0.125,-64) [-64|64] "meters/sec" XXX
 SG_ Length : 10|6@1+ (0.125,0) [0|7.875] "m" XXX
 SG_ dZ : 16|6@1+ (0.25,-5) [-5|10.75] "m" XXX
 SG_ MovingState : 22|2@1+ (1,0) [0|3] "" XXX
 SG_ dxSigma : 24|6@1+ (1,0) [0|63] "" XXX
 SG_ vxSigma : 30|6@1+ (1,0) [0|63] "" XXX
 SG_ axSigma : 36|6@1+ (1,0) [0|63] "" XXX
 SG_ dySigma : 42|6@1+ (1,0) [0|63] "" XXX
 SG_ ProbClass : 48|5@1+ (3.125,0) [0|96.875] "%" XXX
 SG_ Class : 53|3@1+ (1,0) [0|7] "" XXX
 SG_ dxRearEndLoss : 56|6@1+ (1,0) [0|63] "" XXX
 SG_ NotUsed : 62|1@1+ (1,0) [0|1] "" XXX
 SG_ Index2 : 63|1@1+ (1,0) [0|1] "" XXX

BO_ 853 M_355hex: 8 XXX
 SG_ LongDist : 0|12@1+ (0.0625,0) [0|255.9] "meters" XXX
 SG_ LongSpeed : 12|12@1+ (0.0625,-128) [-128|128] "meters/sec" XXX
 SG_ LatDist : 24|11@1+ (0.125,-128) [-128|128] "meters" XXX
 SG_ ProbExist : 35|5@1+ (3.125,0) [0|96.875] "%" XXX
 SG_ LongAccel : 40|10@1+ (0.03125,-16) [-16|16] "meters/sec/sec" XXX
 SG_ ProbObstacle : 50|5@1+ (3.125,0) [0|96.875] "%" XXX
 SG_ Valid : 55|1@1+ (1,0) [0|1] "" XXX
 SG_ ProbNonObstacle : 56|5@1+ (3.125,0) [0|96.875] "%" XXX
 SG_ Meas : 61|1@1+ (1,0) [0|1] "" XXX
 SG_ Tracked : 62|1@1+ (1,0) [0|1] "" XXX
 SG_ Index : 63|1@1+ (1,0) [0|1] "" XXX

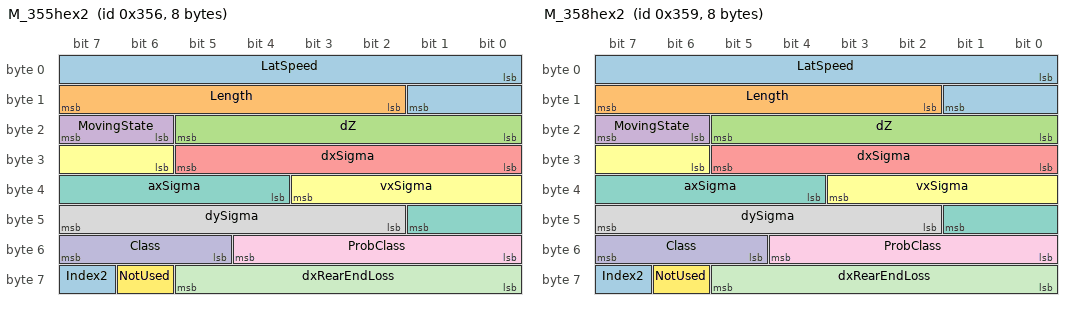
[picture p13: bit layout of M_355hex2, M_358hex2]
BO_ 854 M_355hex2: 8 XXX
 SG_ LatSpeed : 0|10@1+ (0.125,-64) [-64|64] "meters/sec" XXX
 SG_ Length : 10|6@1+ (0.125,0) [0|7.875] "m" XXX
 SG_ dZ : 16|6@1+ (0.25,-5) [-5|10.75] "m" XXX
 SG_ MovingState : 22|2@1+ (1,0) [0|3] "" XXX
 SG_ dxSigma : 24|6@1+ (1,0) [0|63] "" XXX
 SG_ vxSigma : 30|6@1+ (1,0) [0|63] "" XXX
 SG_ axSigma : 36|6@1+ (1,0) [0|63] "" XXX
 SG_ dySigma : 42|6@1+ (1,0) [0|63] "" XXX
 SG_ ProbClass : 48|5@1+ (3.125,0) [0|96.875] "%" XXX
 SG_ Class : 53|3@1+ (1,0) [0|7] "" XXX
 SG_ dxRearEndLoss : 56|6@1+ (1,0) [0|63] "" XXX
 SG_ NotUsed : 62|1@1+ (1,0) [0|1] "" XXX
 SG_ Index2 : 63|1@1+ (1,0) [0|1] "" XXX

BO_ 856 M_358hex: 8 XXX
 SG_ LongDist : 0|12@1+ (0.0625,0) [0|255.9] "meters" XXX
 SG_ LongSpeed : 12|12@1+ (0.0625,-128) [-128|128] "meters/sec" XXX
 SG_ LatDist : 24|11@1+ (0.125,-128) [-128|128] "meters" XXX
 SG_ ProbExist : 35|5@1+ (3.125,0) [0|96.875] "%" XXX
 SG_ LongAccel : 40|10@1+ (0.03125,-16) [-16|16] "meters/sec/sec" XXX
 SG_ ProbObstacle : 50|5@1+ (3.125,0) [0|96.875] "%" XXX
 SG_ Valid : 55|1@1+ (1,0) [0|1] "" XXX
 SG_ ProbNonObstacle : 56|5@1+ (3.125,0) [0|96.875] "%" XXX
 SG_ Meas : 61|1@1+ (1,0) [0|1] "" XXX
 SG_ Tracked : 62|1@1+ (1,0) [0|1] "" XXX
 SG_ Index : 63|1@1+ (1,0) [0|1] "" XXX

BO_ 857 M_358hex2: 8 XXX
 SG_ LatSpeed : 0|10@1+ (0.125,-64) [-64|64] "meters/sec" XXX
 SG_ Length : 10|6@1+ (0.125,0) [0|7.875] "m" XXX
 SG_ dZ : 16|6@1+ (0.25,-5) [-5|10.75] "m" XXX
 SG_ MovingState : 22|2@1+ (1,0) [0|3] "" XXX
 SG_ dxSigma : 24|6@1+ (1,0) [0|63] "" XXX
 SG_ vxSigma : 30|6@1+ (1,0) [0|63] "" XXX
 SG_ axSigma : 36|6@1+ (1,0) [0|63] "" XXX
 SG_ dySigma : 42|6@1+ (1,0) [0|63] "" XXX
 SG_ ProbClass : 48|5@1+ (3.125,0) [0|96.875] "%" XXX
 SG_ Class : 53|3@1+ (1,0) [0|7] "" XXX
 SG_ dxRearEndLoss : 56|6@1+ (1,0) [0|63] "" XXX
 SG_ NotUsed : 62|1@1+ (1,0) [0|1] "" XXX
 SG_ Index2 : 63|1@1+ (1,0) [0|1] "" XXX

BO_ 859 M_35Bhex: 8 XXX
 SG_ LongDist : 0|12@1+ (0.0625,0) [0|255.9] "meters" XXX
 SG_ LongSpeed : 12|12@1+ (0.0625,-128) [-128|128] "meters/sec" XXX
 SG_ LatDist : 24|11@1+ (0.125,-128) [-128|128] "meters" XXX
 SG_ ProbExist : 35|5@1+ (3.125,0) [0|96.875] "%" XXX
 SG_ LongAccel : 40|10@1+ (0.03125,-16) [-16|16] "meters/sec/sec" XXX
 SG_ ProbObstacle : 50|5@1+ (3.125,0) [0|96.875] "%" XXX
 SG_ Valid : 55|1@1+ (1,0) [0|1] "" XXX
 SG_ ProbNonObstacle : 56|5@1+ (3.125,0) [0|96.875] "%" XXX
 SG_ Meas : 61|1@1+ (1,0) [0|1] "" XXX
 SG_ Tracked : 62|1@1+ (1,0) [0|1] "" XXX
 SG_ Index : 63|1@1+ (1,0) [0|1] "" XXX

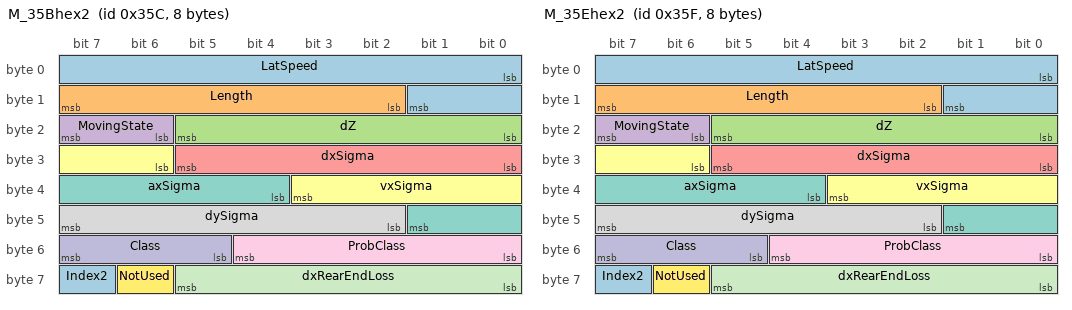
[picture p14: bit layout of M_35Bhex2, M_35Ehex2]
BO_ 860 M_35Bhex2: 8 XXX
 SG_ LatSpeed : 0|10@1+ (0.125,-64) [-64|64] "meters/sec" XXX
 SG_ Length : 10|6@1+ (0.125,0) [0|7.875] "m" XXX
 SG_ dZ : 16|6@1+ (0.25,-5) [-5|10.75] "m" XXX
 SG_ MovingState : 22|2@1+ (1,0) [0|3] "" XXX
 SG_ dxSigma : 24|6@1+ (1,0) [0|63] "" XXX
 SG_ vxSigma : 30|6@1+ (1,0) [0|63] "" XXX
 SG_ axSigma : 36|6@1+ (1,0) [0|63] "" XXX
 SG_ dySigma : 42|6@1+ (1,0) [0|63] "" XXX
 SG_ ProbClass : 48|5@1+ (3.125,0) [0|96.875] "%" XXX
 SG_ Class : 53|3@1+ (1,0) [0|7] "" XXX
 SG_ dxRearEndLoss : 56|6@1+ (1,0) [0|63] "" XXX
 SG_ NotUsed : 62|1@1+ (1,0) [0|1] "" XXX
 SG_ Index2 : 63|1@1+ (1,0) [0|1] "" XXX

BO_ 862 M_35Ehex: 8 XXX
 SG_ LongDist : 0|12@1+ (0.0625,0) [0|255.9] "meters" XXX
 SG_ LongSpeed : 12|12@1+ (0.0625,-128) [-128|128] "meters/sec" XXX
 SG_ LatDist : 24|11@1+ (0.125,-128) [-128|128] "meters" XXX
 SG_ ProbExist : 35|5@1+ (3.125,0) [0|96.875] "%" XXX
 SG_ LongAccel : 40|10@1+ (0.03125,-16) [-16|16] "meters/sec/sec" XXX
 SG_ ProbObstacle : 50|5@1+ (3.125,0) [0|96.875] "%" XXX
 SG_ Valid : 55|1@1+ (1,0) [0|1] "" XXX
 SG_ ProbNonObstacle : 56|5@1+ (3.125,0) [0|96.875] "%" XXX
 SG_ Meas : 61|1@1+ (1,0) [0|1] "" XXX
 SG_ Tracked : 62|1@1+ (1,0) [0|1] "" XXX
 SG_ Index : 63|1@1+ (1,0) [0|1] "" XXX

BO_ 863 M_35Ehex2: 8 XXX
 SG_ LatSpeed : 0|10@1+ (0.125,-64) [-64|64] "meters/sec" XXX
 SG_ Length : 10|6@1+ (0.125,0) [0|7.875] "m" XXX
 SG_ dZ : 16|6@1+ (0.25,-5) [-5|10.75] "m" XXX
 SG_ MovingState : 22|2@1+ (1,0) [0|3] "" XXX
 SG_ dxSigma : 24|6@1+ (1,0) [0|63] "" XXX
 SG_ vxSigma : 30|6@1+ (1,0) [0|63] "" XXX
 SG_ axSigma : 36|6@1+ (1,0) [0|63] "" XXX
 SG_ dySigma : 42|6@1+ (1,0) [0|63] "" XXX
 SG_ ProbClass : 48|5@1+ (3.125,0) [0|96.875] "%" XXX
 SG_ Class : 53|3@1+ (1,0) [0|7] "" XXX
 SG_ dxRearEndLoss : 56|6@1+ (1,0) [0|63] "" XXX
 SG_ NotUsed : 62|1@1+ (1,0) [0|1] "" XXX
 SG_ Index2 : 63|1@1+ (1,0) [0|1] "" XXX

BO_ 865 M_361hex: 8 XXX
 SG_ LongDist : 0|12@1+ (0.0625,0) [0|255.9] "meters" XXX
 SG_ LongSpeed : 12|12@1+ (0.0625,-128) [-128|128] "meters/sec" XXX
 SG_ LatDist : 24|11@1+ (0.125,-128) [-128|128] "meters" XXX
 SG_ ProbExist : 35|5@1+ (3.125,0) [0|96.875] "%" XXX
 SG_ LongAccel : 40|10@1+ (0.03125,-16) [-16|16] "meters/sec/sec" XXX
 SG_ ProbObstacle : 50|5@1+ (3.125,0) [0|96.875] "%" XXX
 SG_ Valid : 55|1@1+ (1,0) [0|1] "" XXX
 SG_ ProbNonObstacle : 56|5@1+ (3.125,0) [0|96.875] "%" XXX
 SG_ Meas : 61|1@1+ (1,0) [0|1] "" XXX
 SG_ Tracked : 62|1@1+ (1,0) [0|1] "" XXX
 SG_ Index : 63|1@1+ (1,0) [0|1] "" XXX

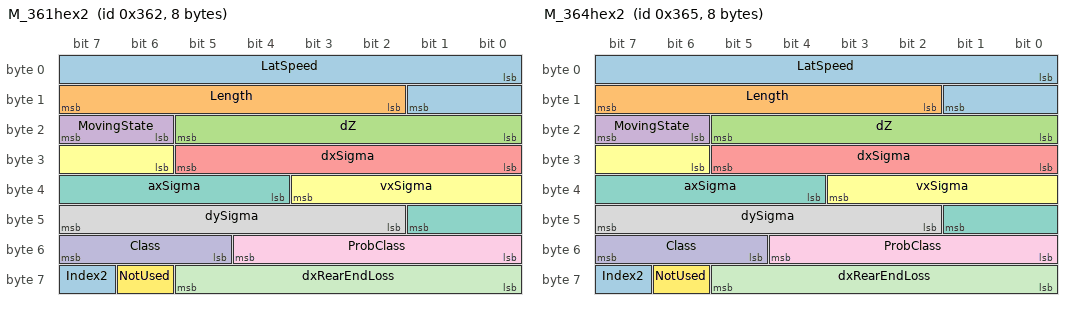
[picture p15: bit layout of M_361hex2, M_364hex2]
BO_ 866 M_361hex2: 8 XXX
 SG_ LatSpeed : 0|10@1+ (0.125,-64) [-64|64] "meters/sec" XXX
 SG_ Length : 10|6@1+ (0.125,0) [0|7.875] "m" XXX
 SG_ dZ : 16|6@1+ (0.25,-5) [-5|10.75] "m" XXX
 SG_ MovingState : 22|2@1+ (1,0) [0|3] "" XXX
 SG_ dxSigma : 24|6@1+ (1,0) [0|63] "" XXX
 SG_ vxSigma : 30|6@1+ (1,0) [0|63] "" XXX
 SG_ axSigma : 36|6@1+ (1,0) [0|63] "" XXX
 SG_ dySigma : 42|6@1+ (1,0) [0|63] "" XXX
 SG_ ProbClass : 48|5@1+ (3.125,0) [0|96.875] "%" XXX
 SG_ Class : 53|3@1+ (1,0) [0|7] "" XXX
 SG_ dxRearEndLoss : 56|6@1+ (1,0) [0|63] "" XXX
 SG_ NotUsed : 62|1@1+ (1,0) [0|1] "" XXX
 SG_ Index2 : 63|1@1+ (1,0) [0|1] "" XXX

BO_ 868 M_364hex: 8 XXX
 SG_ LongDist : 0|12@1+ (0.0625,0) [0|255.9] "meters" XXX
 SG_ LongSpeed : 12|12@1+ (0.0625,-128) [-128|128] "meters/sec" XXX
 SG_ LatDist : 24|11@1+ (0.125,-128) [-128|128] "meters" XXX
 SG_ ProbExist : 35|5@1+ (3.125,0) [0|96.875] "%" XXX
 SG_ LongAccel : 40|10@1+ (0.03125,-16) [-16|16] "meters/sec/sec" XXX
 SG_ ProbObstacle : 50|5@1+ (3.125,0) [0|96.875] "%" XXX
 SG_ Valid : 55|1@1+ (1,0) [0|1] "" XXX
 SG_ ProbNonObstacle : 56|5@1+ (3.125,0) [0|96.875] "%" XXX
 SG_ Meas : 61|1@1+ (1,0) [0|1] "" XXX
 SG_ Tracked : 62|1@1+ (1,0) [0|1] "" XXX
 SG_ Index : 63|1@1+ (1,0) [0|1] "" XXX

BO_ 869 M_364hex2: 8 XXX
 SG_ LatSpeed : 0|10@1+ (0.125,-64) [-64|64] "meters/sec" XXX
 SG_ Length : 10|6@1+ (0.125,0) [0|7.875] "m" XXX
 SG_ dZ : 16|6@1+ (0.25,-5) [-5|10.75] "m" XXX
 SG_ MovingState : 22|2@1+ (1,0) [0|3] "" XXX
 SG_ dxSigma : 24|6@1+ (1,0) [0|63] "" XXX
 SG_ vxSigma : 30|6@1+ (1,0) [0|63] "" XXX
 SG_ axSigma : 36|6@1+ (1,0) [0|63] "" XXX
 SG_ dySigma : 42|6@1+ (1,0) [0|63] "" XXX
 SG_ ProbClass : 48|5@1+ (3.125,0) [0|96.875] "%" XXX
 SG_ Class : 53|3@1+ (1,0) [0|7] "" XXX
 SG_ dxRearEndLoss : 56|6@1+ (1,0) [0|63] "" XXX
 SG_ NotUsed : 62|1@1+ (1,0) [0|1] "" XXX
 SG_ Index2 : 63|1@1+ (1,0) [0|1] "" XXX

BO_ 871 M_367hex: 8 XXX
 SG_ LongDist : 0|12@1+ (0.0625,0) [0|255.9] "meters" XXX
 SG_ LongSpeed : 12|12@1+ (0.0625,-128) [-128|128] "meters/sec" XXX
 SG_ LatDist : 24|11@1+ (0.125,-128) [-128|128] "meters" XXX
 SG_ ProbExist : 35|5@1+ (3.125,0) [0|96.875] "%" XXX
 SG_ LongAccel : 40|10@1+ (0.03125,-16) [-16|16] "meters/sec/sec" XXX
 SG_ ProbObstacle : 50|5@1+ (3.125,0) [0|96.875] "%" XXX
 SG_ Valid : 55|1@1+ (1,0) [0|1] "" XXX
 SG_ ProbNonObstacle : 56|5@1+ (3.125,0) [0|96.875] "%" XXX
 SG_ Meas : 61|1@1+ (1,0) [0|1] "" XXX
 SG_ Tracked : 62|1@1+ (1,0) [0|1] "" XXX
 SG_ Index : 63|1@1+ (1,0) [0|1] "" XXX

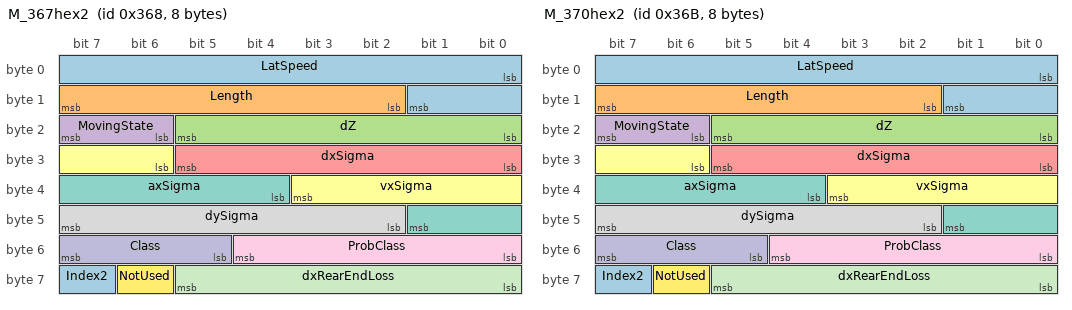
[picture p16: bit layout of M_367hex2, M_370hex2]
BO_ 872 M_367hex2: 8 XXX
 SG_ LatSpeed : 0|10@1+ (0.125,-64) [-64|64] "meters/sec" XXX
 SG_ Length : 10|6@1+ (0.125,0) [0|7.875] "m" XXX
 SG_ dZ : 16|6@1+ (0.25,-5) [-5|10.75] "m" XXX
 SG_ MovingState : 22|2@1+ (1,0) [0|3] "" XXX
 SG_ dxSigma : 24|6@1+ (1,0) [0|63] "" XXX
 SG_ vxSigma : 30|6@1+ (1,0) [0|63] "" XXX
 SG_ axSigma : 36|6@1+ (1,0) [0|63] "" XXX
 SG_ dySigma : 42|6@1+ (1,0) [0|63] "" XXX
 SG_ ProbClass : 48|5@1+ (3.125,0) [0|96.875] "%" XXX
 SG_ Class : 53|3@1+ (1,0) [0|7] "" XXX
 SG_ dxRearEndLoss : 56|6@1+ (1,0) [0|63] "" XXX
 SG_ NotUsed : 62|1@1+ (1,0) [0|1] "" XXX
 SG_ Index2 : 63|1@1+ (1,0) [0|1] "" XXX

BO_ 874 M_370hex: 8 XXX
 SG_ LongDist : 0|12@1+ (0.0625,0) [0|255.9] "meters" XXX
 SG_ LongSpeed : 12|12@1+ (0.0625,-128) [-128|128] "meters/sec" XXX
 SG_ LatDist : 24|11@1+ (0.125,-128) [-128|128] "meters" XXX
 SG_ ProbExist : 35|5@1+ (3.125,0) [0|96.875] "%" XXX
 SG_ LongAccel : 40|10@1+ (0.03125,-16) [-16|16] "meters/sec/sec" XXX
 SG_ ProbObstacle : 50|5@1+ (3.125,0) [0|96.875] "%" XXX
 SG_ Valid : 55|1@1+ (1,0) [0|1] "" XXX
 SG_ ProbNonObstacle : 56|5@1+ (3.125,0) [0|96.875] "%" XXX
 SG_ Meas : 61|1@1+ (1,0) [0|1] "" XXX
 SG_ Tracked : 62|1@1+ (1,0) [0|1] "" XXX
 SG_ Index : 63|1@1+ (1,0) [0|1] "" XXX

BO_ 875 M_370hex2: 8 XXX
 SG_ LatSpeed : 0|10@1+ (0.125,-64) [-64|64] "meters/sec" XXX
 SG_ Length : 10|6@1+ (0.125,0) [0|7.875] "m" XXX
 SG_ dZ : 16|6@1+ (0.25,-5) [-5|10.75] "m" XXX
 SG_ MovingState : 22|2@1+ (1,0) [0|3] "" XXX
 SG_ dxSigma : 24|6@1+ (1,0) [0|63] "" XXX
 SG_ vxSigma : 30|6@1+ (1,0) [0|63] "" XXX
 SG_ axSigma : 36|6@1+ (1,0) [0|63] "" XXX
 SG_ dySigma : 42|6@1+ (1,0) [0|63] "" XXX
 SG_ ProbClass : 48|5@1+ (3.125,0) [0|96.875] "%" XXX
 SG_ Class : 53|3@1+ (1,0) [0|7] "" XXX
 SG_ dxRearEndLoss : 56|6@1+ (1,0) [0|63] "" XXX
 SG_ NotUsed : 62|1@1+ (1,0) [0|1] "" XXX
 SG_ Index2 : 63|1@1+ (1,0) [0|1] "" XXX

BO_ 877 M_373hex: 8 XXX
 SG_ LongDist : 0|12@1+ (0.0625,0) [0|255.9] "meters" XXX
 SG_ LongSpeed : 12|12@1+ (0.0625,-128) [-128|128] "meters/sec" XXX
 SG_ LatDist : 24|11@1+ (0.125,-128) [-128|128] "meters" XXX
 SG_ ProbExist : 35|5@1+ (3.125,0) [0|96.875] "%" XXX
 SG_ LongAccel : 40|10@1+ (0.03125,-16) [-16|16] "meters/sec/sec" XXX
 SG_ ProbObstacle : 50|5@1+ (3.125,0) [0|96.875] "%" XXX
 SG_ Valid : 55|1@1+ (1,0) [0|1] "" XXX
 SG_ ProbNonObstacle : 56|5@1+ (3.125,0) [0|96.875] "%" XXX
 SG_ Meas : 61|1@1+ (1,0) [0|1] "" XXX
 SG_ Tracked : 62|1@1+ (1,0) [0|1] "" XXX
 SG_ Index : 63|1@1+ (1,0) [0|1] "" XXX

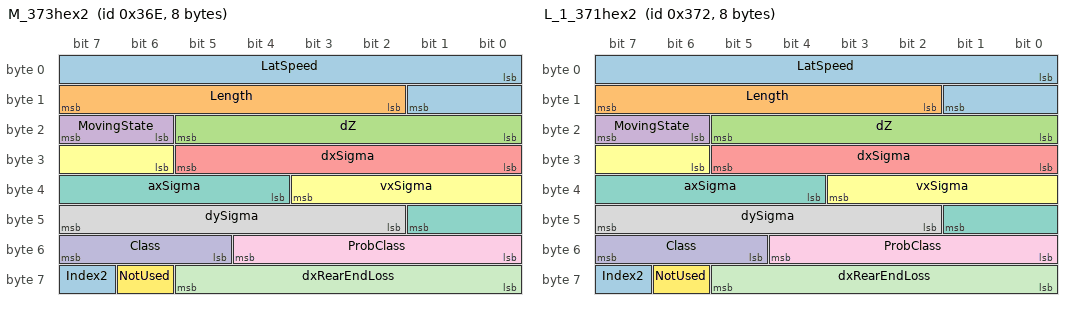
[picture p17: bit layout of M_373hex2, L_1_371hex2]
BO_ 878 M_373hex2: 8 XXX
 SG_ LatSpeed : 0|10@1+ (0.125,-64) [-64|64] "meters/sec" XXX
 SG_ Length : 10|6@1+ (0.125,0) [0|7.875] "m" XXX
 SG_ dZ : 16|6@1+ (0.25,-5) [-5|10.75] "m" XXX
 SG_ MovingState : 22|2@1+ (1,0) [0|3] "" XXX
 SG_ dxSigma : 24|6@1+ (1,0) [0|63] "" XXX
 SG_ vxSigma : 30|6@1+ (1,0) [0|63] "" XXX
 SG_ axSigma : 36|6@1+ (1,0) [0|63] "" XXX
 SG_ dySigma : 42|6@1+ (1,0) [0|63] "" XXX
 SG_ ProbClass : 48|5@1+ (3.125,0) [0|96.875] "%" XXX
 SG_ Class : 53|3@1+ (1,0) [0|7] "" XXX
 SG_ dxRearEndLoss : 56|6@1+ (1,0) [0|63] "" XXX
 SG_ NotUsed : 62|1@1+ (1,0) [0|1] "" XXX
 SG_ Index2 : 63|1@1+ (1,0) [0|1] "" XXX

BO_ 881 L_1_371hex: 8 XXX
 SG_ LongDist : 0|12@1+ (0.0625,0) [0|255.9] "meters" XXX
 SG_ LongSpeed : 12|12@1+ (0.0625,-128) [-128|128] "meters/sec" XXX
 SG_ LatDist : 24|11@1+ (0.125,-128) [-128|128] "meters" XXX
 SG_ ProbExist : 35|5@1+ (3.125,0) [0|96.875] "%" XXX
 SG_ LongAccel : 40|10@1+ (0.03125,-16) [-16|16] "meters/sec/sec" XXX
 SG_ ProbObstacle : 50|5@1+ (3.125,0) [0|96.875] "%" XXX
 SG_ Valid : 55|1@1+ (1,0) [0|1] "" XXX
 SG_ ProbNonObstacle : 56|5@1+ (3.125,0) [0|96.875] "%" XXX
 SG_ Meas : 61|1@1+ (1,0) [0|1] "" XXX
 SG_ Tracked : 62|1@1+ (1,0) [0|1] "" XXX
 SG_ Index : 63|1@1+ (1,0) [0|1] "" XXX

BO_ 882 L_1_371hex2: 8 XXX
 SG_ LatSpeed : 0|10@1+ (0.125,-64) [-64|64] "meters/sec" XXX
 SG_ Length : 10|6@1+ (0.125,0) [0|7.875] "m" XXX
 SG_ dZ : 16|6@1+ (0.25,-5) [-5|10.75] "m" XXX
 SG_ MovingState : 22|2@1+ (1,0) [0|3] "" XXX
 SG_ dxSigma : 24|6@1+ (1,0) [0|63] "" XXX
 SG_ vxSigma : 30|6@1+ (1,0) [0|63] "" XXX
 SG_ axSigma : 36|6@1+ (1,0) [0|63] "" XXX
 SG_ dySigma : 42|6@1+ (1,0) [0|63] "" XXX
 SG_ ProbClass : 48|5@1+ (3.125,0) [0|96.875] "%" XXX
 SG_ Class : 53|3@1+ (1,0) [0|7] "" XXX
 SG_ dxRearEndLoss : 56|6@1+ (1,0) [0|63] "" XXX
 SG_ NotUsed : 62|1@1+ (1,0) [0|1] "" XXX
 SG_ Index2 : 63|1@1+ (1,0) [0|1] "" XXX

BO_ 884 L_2_374hex: 8 XXX
 SG_ LongDist : 0|12@1+ (0.0625,0) [0|255.9] "meters" XXX
 SG_ LongSpeed : 12|12@1+ (0.0625,-128) [-128|128] "meters/sec" XXX
 SG_ LatDist : 24|11@1+ (0.125,-128) [-128|128] "meters" XXX
 SG_ ProbExist : 35|5@1+ (3.125,0) [0|96.875] "%" XXX
 SG_ LongAccel : 40|10@1+ (0.03125,-16) [-16|16] "meters/sec/sec" XXX
 SG_ ProbObstacle : 50|5@1+ (3.125,0) [0|96.875] "%" XXX
 SG_ Valid : 55|1@1+ (1,0) [0|1] "" XXX
 SG_ ProbNonObstacle : 56|5@1+ (3.125,0) [0|96.875] "%" XXX
 SG_ Meas : 61|1@1+ (1,0) [0|1] "" XXX
 SG_ Tracked : 62|1@1+ (1,0) [0|1] "" XXX
 SG_ Index : 63|1@1+ (1,0) [0|1] "" XXX

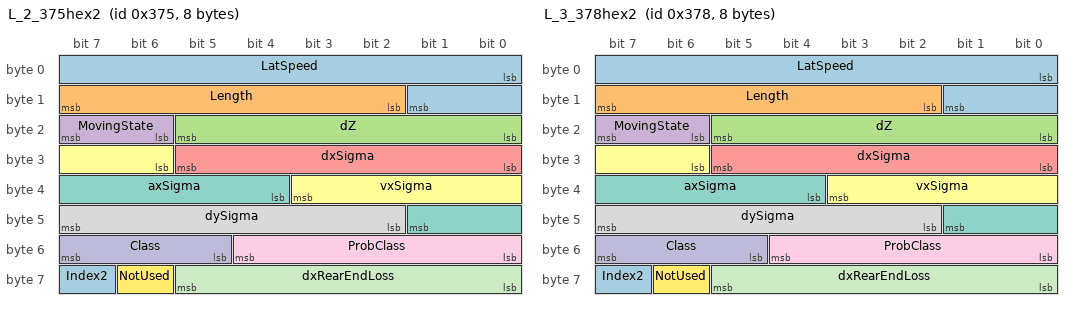
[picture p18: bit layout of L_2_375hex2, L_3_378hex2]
BO_ 885 L_2_375hex2: 8 XXX
 SG_ LatSpeed : 0|10@1+ (0.125,-64) [-64|64] "meters/sec" XXX
 SG_ Length : 10|6@1+ (0.125,0) [0|7.875] "m" XXX
 SG_ dZ : 16|6@1+ (0.25,-5) [-5|10.75] "m" XXX
 SG_ MovingState : 22|2@1+ (1,0) [0|3] "" XXX
 SG_ dxSigma : 24|6@1+ (1,0) [0|63] "" XXX
 SG_ vxSigma : 30|6@1+ (1,0) [0|63] "" XXX
 SG_ axSigma : 36|6@1+ (1,0) [0|63] "" XXX
 SG_ dySigma : 42|6@1+ (1,0) [0|63] "" XXX
 SG_ ProbClass : 48|5@1+ (3.125,0) [0|96.875] "%" XXX
 SG_ Class : 53|3@1+ (1,0) [0|7] "" XXX
 SG_ dxRearEndLoss : 56|6@1+ (1,0) [0|63] "" XXX
 SG_ NotUsed : 62|1@1+ (1,0) [0|1] "" XXX
 SG_ Index2 : 63|1@1+ (1,0) [0|1] "" XXX

BO_ 887 L_3_377hex: 8 XXX
 SG_ LongDist : 0|12@1+ (0.0625,0) [0|255.9] "meters" XXX
 SG_ LongSpeed : 12|12@1+ (0.0625,-128) [-128|128] "meters/sec" XXX
 SG_ LatDist : 24|11@1+ (0.125,-128) [-128|128] "meters" XXX
 SG_ ProbExist : 35|5@1+ (3.125,0) [0|96.875] "%" XXX
 SG_ LongAccel : 40|10@1+ (0.03125,-16) [-16|16] "meters/sec/sec" XXX
 SG_ ProbObstacle : 50|5@1+ (3.125,0) [0|96.875] "%" XXX
 SG_ Valid : 55|1@1+ (1,0) [0|1] "" XXX
 SG_ ProbNonObstacle : 56|5@1+ (3.125,0) [0|96.875] "%" XXX
 SG_ Meas : 61|1@1+ (1,0) [0|1] "" XXX
 SG_ Tracked : 62|1@1+ (1,0) [0|1] "" XXX
 SG_ Index : 63|1@1+ (1,0) [0|1] "" XXX

BO_ 888 L_3_378hex2: 8 XXX
 SG_ LatSpeed : 0|10@1+ (0.125,-64) [-64|64] "meters/sec" XXX
 SG_ Length : 10|6@1+ (0.125,0) [0|7.875] "m" XXX
 SG_ dZ : 16|6@1+ (0.25,-5) [-5|10.75] "m" XXX
 SG_ MovingState : 22|2@1+ (1,0) [0|3] "" XXX
 SG_ dxSigma : 24|6@1+ (1,0) [0|63] "" XXX
 SG_ vxSigma : 30|6@1+ (1,0) [0|63] "" XXX
 SG_ axSigma : 36|6@1+ (1,0) [0|63] "" XXX
 SG_ dySigma : 42|6@1+ (1,0) [0|63] "" XXX
 SG_ ProbClass : 48|5@1+ (3.125,0) [0|96.875] "%" XXX
 SG_ Class : 53|3@1+ (1,0) [0|7] "" XXX
 SG_ dxRearEndLoss : 56|6@1+ (1,0) [0|63] "" XXX
 SG_ NotUsed : 62|1@1+ (1,0) [0|1] "" XXX
 SG_ Index2 : 63|1@1+ (1,0) [0|1] "" XXX

BO_ 890 L_4_37ahex: 8 XXX
 SG_ LongDist : 0|12@1+ (0.0625,0) [0|255.9] "meters" XXX
 SG_ LongSpeed : 12|12@1+ (0.0625,-128) [-128|128] "meters/sec" XXX
 SG_ LatDist : 24|11@1+ (0.125,-128) [-128|128] "meters" XXX
 SG_ ProbExist : 35|5@1+ (3.125,0) [0|96.875] "%" XXX
 SG_ LongAccel : 40|10@1+ (0.03125,-16) [-16|16] "meters/sec/sec" XXX
 SG_ ProbObstacle : 50|5@1+ (3.125,0) [0|96.875] "%" XXX
 SG_ Valid : 55|1@1+ (1,0) [0|1] "" XXX
 SG_ ProbNonObstacle : 56|5@1+ (3.125,0) [0|96.875] "%" XXX
 SG_ Meas : 61|1@1+ (1,0) [0|1] "" XXX
 SG_ Tracked : 62|1@1+ (1,0) [0|1] "" XXX
 SG_ Index : 63|1@1+ (1,0) [0|1] "" XXX

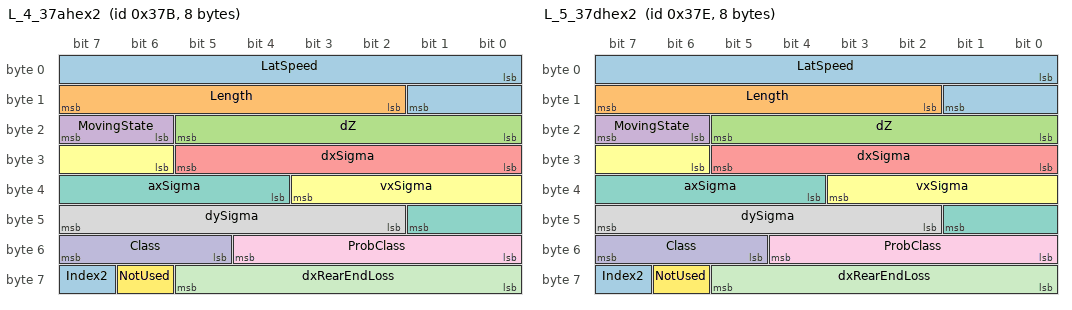
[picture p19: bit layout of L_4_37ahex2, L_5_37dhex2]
BO_ 891 L_4_37ahex2: 8 XXX
 SG_ LatSpeed : 0|10@1+ (0.125,-64) [-64|64] "meters/sec" XXX
 SG_ Length : 10|6@1+ (0.125,0) [0|7.875] "m" XXX
 SG_ dZ : 16|6@1+ (0.25,-5) [-5|10.75] "m" XXX
 SG_ MovingState : 22|2@1+ (1,0) [0|3] "" XXX
 SG_ dxSigma : 24|6@1+ (1,0) [0|63] "" XXX
 SG_ vxSigma : 30|6@1+ (1,0) [0|63] "" XXX
 SG_ axSigma : 36|6@1+ (1,0) [0|63] "" XXX
 SG_ dySigma : 42|6@1+ (1,0) [0|63] "" XXX
 SG_ ProbClass : 48|5@1+ (3.125,0) [0|96.875] "%" XXX
 SG_ Class : 53|3@1+ (1,0) [0|7] "" XXX
 SG_ dxRearEndLoss : 56|6@1+ (1,0) [0|63] "" XXX
 SG_ NotUsed : 62|1@1+ (1,0) [0|1] "" XXX
 SG_ Index2 : 63|1@1+ (1,0) [0|1] "" XXX

BO_ 893 L_5_37dhex: 8 XXX
 SG_ LongDist : 0|12@1+ (0.0625,0) [0|255.9] "meters" XXX
 SG_ LongSpeed : 12|12@1+ (0.0625,-128) [-128|128] "meters/sec" XXX
 SG_ LatDist : 24|11@1+ (0.125,-128) [-128|128] "meters" XXX
 SG_ ProbExist : 35|5@1+ (3.125,0) [0|96.875] "%" XXX
 SG_ LongAccel : 40|10@1+ (0.03125,-16) [-16|16] "meters/sec/sec" XXX
 SG_ ProbObstacle : 50|5@1+ (3.125,0) [0|96.875] "%" XXX
 SG_ Valid : 55|1@1+ (1,0) [0|1] "" XXX
 SG_ ProbNonObstacle : 56|5@1+ (3.125,0) [0|96.875] "%" XXX
 SG_ Meas : 61|1@1+ (1,0) [0|1] "" XXX
 SG_ Tracked : 62|1@1+ (1,0) [0|1] "" XXX
 SG_ Index : 63|1@1+ (1,0) [0|1] "" XXX

BO_ 894 L_5_37dhex2: 8 XXX
 SG_ LatSpeed : 0|10@1+ (0.125,-64) [-64|64] "meters/sec" XXX
 SG_ Length : 10|6@1+ (0.125,0) [0|7.875] "m" XXX
 SG_ dZ : 16|6@1+ (0.25,-5) [-5|10.75] "m" XXX
 SG_ MovingState : 22|2@1+ (1,0) [0|3] "" XXX
 SG_ dxSigma : 24|6@1+ (1,0) [0|63] "" XXX
 SG_ vxSigma : 30|6@1+ (1,0) [0|63] "" XXX
 SG_ axSigma : 36|6@1+ (1,0) [0|63] "" XXX
 SG_ dySigma : 42|6@1+ (1,0) [0|63] "" XXX
 SG_ ProbClass : 48|5@1+ (3.125,0) [0|96.875] "%" XXX
 SG_ Class : 53|3@1+ (1,0) [0|7] "" XXX
 SG_ dxRearEndLoss : 56|6@1+ (1,0) [0|63] "" XXX
 SG_ NotUsed : 62|1@1+ (1,0) [0|1] "" XXX
 SG_ Index2 : 63|1@1+ (1,0) [0|1] "" XXX

VAL_ 785 MovingState 3 "RADAR_MOVESTATE_STANDING" 2 "RADAR_MOVESTATE_STOPPED" 1 "RADAR_MOVESTATE_MOVING" 0 "RADAR_MOVESTATE_INDETERMINATE" ;
VAL_ 785 Class 4 "RADAR_CLASS_CONSTRUCTION_ELEMENT" 3 "RADAR_CLASS_MOVING_PEDESTRIAN" 2 "RADAR_CLASS_MOVING_TWO_WHEEL_VEHICLE" 1 "RADAR_CLASS_MOVING_FOUR_WHEEL_VEHICLE" 0 "RADAR_CLASS_UNKNOWN" ;
VAL_ 788 MovingState 3 "RADAR_MOVESTATE_STANDING" 2 "RADAR_MOVESTATE_STOPPED" 1 "RADAR_MOVESTATE_MOVING" 0 "RADAR_MOVESTATE_INDETERMINATE" ;
VAL_ 788 Class 4 "RADAR_CLASS_CONSTRUCTION_ELEMENT" 3 "RADAR_CLASS_MOVING_PEDESTRIAN" 2 "RADAR_CLASS_MOVING_TWO_WHEEL_VEHICLE" 1 "RADAR_CLASS_MOVING_FOUR_WHEEL_VEHICLE" 0 "RADAR_CLASS_UNKNOWN" ;
VAL_ 791 MovingState 3 "RADAR_MOVESTATE_STANDING" 2 "RADAR_MOVESTATE_STOPPED" 1 "RADAR_MOVESTATE_MOVING" 0 "RADAR_MOVESTATE_INDETERMINATE" ;
VAL_ 791 Class 4 "RADAR_CLASS_CONSTRUCTION_ELEMENT" 3 "RADAR_CLASS_MOVING_PEDESTRIAN" 2 "RADAR_CLASS_MOVING_TWO_WHEEL_VEHICLE" 1 "RADAR_CLASS_MOVING_FOUR_WHEEL_VEHICLE" 0 "RADAR_CLASS_UNKNOWN" ;
VAL_ 794 MovingState 3 "RADAR_MOVESTATE_STANDING" 2 "RADAR_MOVESTATE_STOPPED" 1 "RADAR_MOVESTATE_MOVING" 0 "RADAR_MOVESTATE_INDETERMINATE" ;
VAL_ 794 Class 4 "RADAR_CLASS_CONSTRUCTION_ELEMENT" 3 "RADAR_CLASS_MOVING_PEDESTRIAN" 2 "RADAR_CLASS_MOVING_TWO_WHEEL_VEHICLE" 1 "RADAR_CLASS_MOVING_FOUR_WHEEL_VEHICLE" 0 "RADAR_CLASS_UNKNOWN" ;
VAL_ 797 MovingState 3 "RADAR_MOVESTATE_STANDING" 2 "RADAR_MOVESTATE_STOPPED" 1 "RADAR_MOVESTATE_MOVING" 0 "RADAR_MOVESTATE_INDETERMINATE" ;
VAL_ 797 Class 4 "RADAR_CLASS_CONSTRUCTION_ELEMENT" 3 "RADAR_CLASS_MOVING_PEDESTRIAN" 2 "RADAR_CLASS_MOVING_TWO_WHEEL_VEHICLE" 1 "RADAR_CLASS_MOVING_FOUR_WHEEL_VEHICLE" 0 "RADAR_CLASS_UNKNOWN" ;
VAL_ 800 MovingState 3 "RADAR_MOVESTATE_STANDING" 2 "RADAR_MOVESTATE_STOPPED" 1 "RADAR_MOVESTATE_MOVING" 0 "RADAR_MOVESTATE_INDETERMINATE" ;
VAL_ 800 Class 4 "RADAR_CLASS_CONSTRUCTION_ELEMENT" 3 "RADAR_CLASS_MOVING_PEDESTRIAN" 2 "RADAR_CLASS_MOVING_TWO_WHEEL_VEHICLE" 1 "RADAR_CLASS_MOVING_FOUR_WHEEL_VEHICLE" 0 "RADAR_CLASS_UNKNOWN" ;
VAL_ 803 MovingState 3 "RADAR_MOVESTATE_STANDING" 2 "RADAR_MOVESTATE_STOPPED" 1 "RADAR_MOVESTATE_MOVING" 0 "RADAR_MOVESTATE_INDETERMINATE" ;
VAL_ 803 Class 4 "RADAR_CLASS_CONSTRUCTION_ELEMENT" 3 "RADAR_CLASS_MOVING_PEDESTRIAN" 2 "RADAR_CLASS_MOVING_TWO_WHEEL_VEHICLE" 1 "RADAR_CLASS_MOVING_FOUR_WHEEL_VEHICLE" 0 "RADAR_CLASS_UNKNOWN" ;
VAL_ 806 MovingState 3 "RADAR_MOVESTATE_STANDING" 2 "RADAR_MOVESTATE_STOPPED" 1 "RADAR_MOVESTATE_MOVING" 0 "RADAR_MOVESTATE_INDETERMINATE" ;
VAL_ 806 Class 4 "RADAR_CLASS_CONSTRUCTION_ELEMENT" 3 "RADAR_CLASS_MOVING_PEDESTRIAN" 2 "RADAR_CLASS_MOVING_TWO_WHEEL_VEHICLE" 1 "RADAR_CLASS_MOVING_FOUR_WHEEL_VEHICLE" 0 "RADAR_CLASS_UNKNOWN" ;
VAL_ 809 MovingState 3 "RADAR_MOVESTATE_STANDING" 2 "RADAR_MOVESTATE_STOPPED" 1 "RADAR_MOVESTATE_MOVING" 0 "RADAR_MOVESTATE_INDETERMINATE" ;
VAL_ 809 Class 4 "RADAR_CLASS_CONSTRUCTION_ELEMENT" 3 "RADAR_CLASS_MOVING_PEDESTRIAN" 2 "RADAR_CLASS_MOVING_TWO_WHEEL_VEHICLE" 1 "RADAR_CLASS_MOVING_FOUR_WHEEL_VEHICLE" 0 "RADAR_CLASS_UNKNOWN" ;
VAL_ 812 MovingState 3 "RADAR_MOVESTATE_STANDING" 2 "RADAR_MOVESTATE_STOPPED" 1 "RADAR_MOVESTATE_MOVING" 0 "RADAR_MOVESTATE_INDETERMINATE" ;
VAL_ 812 Class 4 "RADAR_CLASS_CONSTRUCTION_ELEMENT" 3 "RADAR_CLASS_MOVING_PEDESTRIAN" 2 "RADAR_CLASS_MOVING_TWO_WHEEL_VEHICLE" 1 "RADAR_CLASS_MOVING_FOUR_WHEEL_VEHICLE" 0 "RADAR_CLASS_UNKNOWN" ;
VAL_ 815 MovingState 3 "RADAR_MOVESTATE_STANDING" 2 "RADAR_MOVESTATE_STOPPED" 1 "RADAR_MOVESTATE_MOVING" 0 "RADAR_MOVESTATE_INDETERMINATE" ;
VAL_ 815 Class 4 "RADAR_CLASS_CONSTRUCTION_ELEMENT" 3 "RADAR_CLASS_MOVING_PEDESTRIAN" 2 "RADAR_CLASS_MOVING_TWO_WHEEL_VEHICLE" 1 "RADAR_CLASS_MOVING_FOUR_WHEEL_VEHICLE" 0 "RADAR_CLASS_UNKNOWN" ;
VAL_ 818 MovingState 3 "RADAR_MOVESTATE_STANDING" 2 "RADAR_MOVESTATE_STOPPED" 1 "RADAR_MOVESTATE_MOVING" 0 "RADAR_MOVESTATE_INDETERMINATE" ;
VAL_ 818 Class 4 "RADAR_CLASS_CONSTRUCTION_ELEMENT" 3 "RADAR_CLASS_MOVING_PEDESTRIAN" 2 "RADAR_CLASS_MOVING_TWO_WHEEL_VEHICLE" 1 "RADAR_CLASS_MOVING_FOUR_WHEEL_VEHICLE" 0 "RADAR_CLASS_UNKNOWN" ;
VAL_ 821 MovingState 3 "RADAR_MOVESTATE_STANDING" 2 "RADAR_MOVESTATE_STOPPED" 1 "RADAR_MOVESTATE_MOVING" 0 "RADAR_MOVESTATE_INDETERMINATE" ;
VAL_ 821 Class 4 "RADAR_CLASS_CONSTRUCTION_ELEMENT" 3 "RADAR_CLASS_MOVING_PEDESTRIAN" 2 "RADAR_CLASS_MOVING_TWO_WHEEL_VEHICLE" 1 "RADAR_CLASS_MOVING_FOUR_WHEEL_VEHICLE" 0 "RADAR_CLASS_UNKNOWN" ;
VAL_ 824 MovingState 3 "RADAR_MOVESTATE_STANDING" 2 "RADAR_MOVESTATE_STOPPED" 1 "RADAR_MOVESTATE_MOVING" 0 "RADAR_MOVESTATE_INDETERMINATE" ;
VAL_ 824 Class 4 "RADAR_CLASS_CONSTRUCTION_ELEMENT" 3 "RADAR_CLASS_MOVING_PEDESTRIAN" 2 "RADAR_CLASS_MOVING_TWO_WHEEL_VEHICLE" 1 "RADAR_CLASS_MOVING_FOUR_WHEEL_VEHICLE" 0 "RADAR_CLASS_UNKNOWN" ;
VAL_ 827 MovingState 3 "RADAR_MOVESTATE_STANDING" 2 "RADAR_MOVESTATE_STOPPED" 1 "RADAR_MOVESTATE_MOVING" 0 "RADAR_MOVESTATE_INDETERMINATE" ;
VAL_ 827 Class 4 "RADAR_CLASS_CONSTRUCTION_ELEMENT" 3 "RADAR_CLASS_MOVING_PEDESTRIAN" 2 "RADAR_CLASS_MOVING_TWO_WHEEL_VEHICLE" 1 "RADAR_CLASS_MOVING_FOUR_WHEEL_VEHICLE" 0 "RADAR_CLASS_UNKNOWN" ;
VAL_ 830 MovingState 3 "RADAR_MOVESTATE_STANDING" 2 "RADAR_MOVESTATE_STOPPED" 1 "RADAR_MOVESTATE_MOVING" 0 "RADAR_MOVESTATE_INDETERMINATE" ;
VAL_ 830 Class 4 "RADAR_CLASS_CONSTRUCTION_ELEMENT" 3 "RADAR_CLASS_MOVING_PEDESTRIAN" 2 "RADAR_CLASS_MOVING_TWO_WHEEL_VEHICLE" 1 "RADAR_CLASS_MOVING_FOUR_WHEEL_VEHICLE" 0 "RADAR_CLASS_UNKNOWN" ;
VAL_ 833 MovingState 3 "RADAR_MOVESTATE_STANDING" 2 "RADAR_MOVESTATE_STOPPED" 1 "RADAR_MOVESTATE_MOVING" 0 "RADAR_MOVESTATE_INDETERMINATE" ;
VAL_ 833 Class 4 "RADAR_CLASS_CONSTRUCTION_ELEMENT" 3 "RADAR_CLASS_MOVING_PEDESTRIAN" 2 "RADAR_CLASS_MOVING_TWO_WHEEL_VEHICLE" 1 "RADAR_CLASS_MOVING_FOUR_WHEEL_VEHICLE" 0 "RADAR_CLASS_UNKNOWN" ;
VAL_ 836 MovingState 3 "RADAR_MOVESTATE_STANDING" 2 "RADAR_MOVESTATE_STOPPED" 1 "RADAR_MOVESTATE_MOVING" 0 "RADAR_MOVESTATE_INDETERMINATE" ;
VAL_ 836 Class 4 "RADAR_CLASS_CONSTRUCTION_ELEMENT" 3 "RADAR_CLASS_MOVING_PEDESTRIAN" 2 "RADAR_CLASS_MOVING_TWO_WHEEL_VEHICLE" 1 "RADAR_CLASS_MOVING_FOUR_WHEEL_VEHICLE" 0 "RADAR_CLASS_UNKNOWN" ;
VAL_ 839 MovingState 3 "RADAR_MOVESTATE_STANDING" 2 "RADAR_MOVESTATE_STOPPED" 1 "RADAR_MOVESTATE_MOVING" 0 "RADAR_MOVESTATE_INDETERMINATE" ;
VAL_ 839 Class 4 "RADAR_CLASS_CONSTRUCTION_ELEMENT" 3 "RADAR_CLASS_MOVING_PEDESTRIAN" 2 "RADAR_CLASS_MOVING_TWO_WHEEL_VEHICLE" 1 "RADAR_CLASS_MOVING_FOUR_WHEEL_VEHICLE" 0 "RADAR_CLASS_UNKNOWN" ;
VAL_ 842 MovingState 3 "RADAR_MOVESTATE_STANDING" 2 "RADAR_MOVESTATE_STOPPED" 1 "RADAR_MOVESTATE_MOVING" 0 "RADAR_MOVESTATE_INDETERMINATE" ;
VAL_ 842 Class 4 "RADAR_CLASS_CONSTRUCTION_ELEMENT" 3 "RADAR_CLASS_MOVING_PEDESTRIAN" 2 "RADAR_CLASS_MOVING_TWO_WHEEL_VEHICLE" 1 "RADAR_CLASS_MOVING_FOUR_WHEEL_VEHICLE" 0 "RADAR_CLASS_UNKNOWN" ;
VAL_ 845 MovingState 3 "RADAR_MOVESTATE_STANDING" 2 "RADAR_MOVESTATE_STOPPED" 1 "RADAR_MOVESTATE_MOVING" 0 "RADAR_MOVESTATE_INDETERMINATE" ;
VAL_ 845 Class 4 "RADAR_CLASS_CONSTRUCTION_ELEMENT" 3 "RADAR_CLASS_MOVING_PEDESTRIAN" 2 "RADAR_CLASS_MOVING_TWO_WHEEL_VEHICLE" 1 "RADAR_CLASS_MOVING_FOUR_WHEEL_VEHICLE" 0 "RADAR_CLASS_UNKNOWN" ;
VAL_ 848 MovingState 3 "RADAR_MOVESTATE_STANDING" 2 "RADAR_MOVESTATE_STOPPED" 1 "RADAR_MOVESTATE_MOVING" 0 "RADAR_MOVESTATE_INDETERMINATE" ;
VAL_ 848 Class 4 "RADAR_CLASS_CONSTRUCTION_ELEMENT" 3 "RADAR_CLASS_MOVING_PEDESTRIAN" 2 "RADAR_CLASS_MOVING_TWO_WHEEL_VEHICLE" 1 "RADAR_CLASS_MOVING_FOUR_WHEEL_VEHICLE" 0 "RADAR_CLASS_UNKNOWN" ;
VAL_ 851 MovingState 3 "RADAR_MOVESTATE_STANDING" 2 "RADAR_MOVESTATE_STOPPED" 1 "RADAR_MOVESTATE_MOVING" 0 "RADAR_MOVESTATE_INDETERMINATE" ;
VAL_ 851 Class 4 "RADAR_CLASS_CONSTRUCTION_ELEMENT" 3 "RADAR_CLASS_MOVING_PEDESTRIAN" 2 "RADAR_CLASS_MOVING_TWO_WHEEL_VEHICLE" 1 "RADAR_CLASS_MOVING_FOUR_WHEEL_VEHICLE" 0 "RADAR_CLASS_UNKNOWN" ;
VAL_ 854 MovingState 3 "RADAR_MOVESTATE_STANDING" 2 "RADAR_MOVESTATE_STOPPED" 1 "RADAR_MOVESTATE_MOVING" 0 "RADAR_MOVESTATE_INDETERMINATE" ;
VAL_ 854 Class 4 "RADAR_CLASS_CONSTRUCTION_ELEMENT" 3 "RADAR_CLASS_MOVING_PEDESTRIAN" 2 "RADAR_CLASS_MOVING_TWO_WHEEL_VEHICLE" 1 "RADAR_CLASS_MOVING_FOUR_WHEEL_VEHICLE" 0 "RADAR_CLASS_UNKNOWN" ;
VAL_ 857 MovingState 3 "RADAR_MOVESTATE_STANDING" 2 "RADAR_MOVESTATE_STOPPED" 1 "RADAR_MOVESTATE_MOVING" 0 "RADAR_MOVESTATE_INDETERMINATE" ;
VAL_ 857 Class 4 "RADAR_CLASS_CONSTRUCTION_ELEMENT" 3 "RADAR_CLASS_MOVING_PEDESTRIAN" 2 "RADAR_CLASS_MOVING_TWO_WHEEL_VEHICLE" 1 "RADAR_CLASS_MOVING_FOUR_WHEEL_VEHICLE" 0 "RADAR_CLASS_UNKNOWN" ;
VAL_ 860 MovingState 3 "RADAR_MOVESTATE_STANDING" 2 "RADAR_MOVESTATE_STOPPED" 1 "RADAR_MOVESTATE_MOVING" 0 "RADAR_MOVESTATE_INDETERMINATE" ;
VAL_ 860 Class 4 "RADAR_CLASS_CONSTRUCTION_ELEMENT" 3 "RADAR_CLASS_MOVING_PEDESTRIAN" 2 "RADAR_CLASS_MOVING_TWO_WHEEL_VEHICLE" 1 "RADAR_CLASS_MOVING_FOUR_WHEEL_VEHICLE" 0 "RADAR_CLASS_UNKNOWN" ;
VAL_ 863 MovingState 3 "RADAR_MOVESTATE_STANDING" 2 "RADAR_MOVESTATE_STOPPED" 1 "RADAR_MOVESTATE_MOVING" 0 "RADAR_MOVESTATE_INDETERMINATE" ;
VAL_ 863 Class 4 "RADAR_CLASS_CONSTRUCTION_ELEMENT" 3 "RADAR_CLASS_MOVING_PEDESTRIAN" 2 "RADAR_CLASS_MOVING_TWO_WHEEL_VEHICLE" 1 "RADAR_CLASS_MOVING_FOUR_WHEEL_VEHICLE" 0 "RADAR_CLASS_UNKNOWN" ;
VAL_ 866 MovingState 3 "RADAR_MOVESTATE_STANDING" 2 "RADAR_MOVESTATE_STOPPED" 1 "RADAR_MOVESTATE_MOVING" 0 "RADAR_MOVESTATE_INDETERMINATE" ;
VAL_ 866 Class 4 "RADAR_CLASS_CONSTRUCTION_ELEMENT" 3 "RADAR_CLASS_MOVING_PEDESTRIAN" 2 "RADAR_CLASS_MOVING_TWO_WHEEL_VEHICLE" 1 "RADAR_CLASS_MOVING_FOUR_WHEEL_VEHICLE" 0 "RADAR_CLASS_UNKNOWN" ;
VAL_ 869 MovingState 3 "RADAR_MOVESTATE_STANDING" 2 "RADAR_MOVESTATE_STOPPED" 1 "RADAR_MOVESTATE_MOVING" 0 "RADAR_MOVESTATE_INDETERMINATE" ;
VAL_ 869 Class 4 "RADAR_CLASS_CONSTRUCTION_ELEMENT" 3 "RADAR_CLASS_MOVING_PEDESTRIAN" 2 "RADAR_CLASS_MOVING_TWO_WHEEL_VEHICLE" 1 "RADAR_CLASS_MOVING_FOUR_WHEEL_VEHICLE" 0 "RADAR_CLASS_UNKNOWN" ;
VAL_ 872 MovingState 3 "RADAR_MOVESTATE_STANDING" 2 "RADAR_MOVESTATE_STOPPED" 1 "RADAR_MOVESTATE_MOVING" 0 "RADAR_MOVESTATE_INDETERMINATE" ;
VAL_ 872 Class 4 "RADAR_CLASS_CONSTRUCTION_ELEMENT" 3 "RADAR_CLASS_MOVING_PEDESTRIAN" 2 "RADAR_CLASS_MOVING_TWO_WHEEL_VEHICLE" 1 "RADAR_CLASS_MOVING_FOUR_WHEEL_VEHICLE" 0 "RADAR_CLASS_UNKNOWN" ;
VAL_ 875 MovingState 3 "RADAR_MOVESTATE_STANDING" 2 "RADAR_MOVESTATE_STOPPED" 1 "RADAR_MOVESTATE_MOVING" 0 "RADAR_MOVESTATE_INDETERMINATE" ;
VAL_ 875 Class 4 "RADAR_CLASS_CONSTRUCTION_ELEMENT" 3 "RADAR_CLASS_MOVING_PEDESTRIAN" 2 "RADAR_CLASS_MOVING_TWO_WHEEL_VEHICLE" 1 "RADAR_CLASS_MOVING_FOUR_WHEEL_VEHICLE" 0 "RADAR_CLASS_UNKNOWN" ;
VAL_ 878 MovingState 3 "RADAR_MOVESTATE_STANDING" 2 "RADAR_MOVESTATE_STOPPED" 1 "RADAR_MOVESTATE_MOVING" 0 "RADAR_MOVESTATE_INDETERMINATE" ;
VAL_ 878 Class 4 "RADAR_CLASS_CONSTRUCTION_ELEMENT" 3 "RADAR_CLASS_MOVING_PEDESTRIAN" 2 "RADAR_CLASS_MOVING_TWO_WHEEL_VEHICLE" 1 "RADAR_CLASS_MOVING_FOUR_WHEEL_VEHICLE" 0 "RADAR_CLASS_UNKNOWN" ;
VAL_ 882 MovingState 3 "RADAR_MOVESTATE_STANDING" 2 "RADAR_MOVESTATE_STOPPED" 1 "RADAR_MOVESTATE_MOVING" 0 "RADAR_MOVESTATE_INDETERMINATE" ;
VAL_ 882 Class 4 "RADAR_CLASS_CONSTRUCTION_ELEMENT" 3 "RADAR_CLASS_MOVING_PEDESTRIAN" 2 "RADAR_CLASS_MOVING_TWO_WHEEL_VEHICLE" 1 "RADAR_CLASS_MOVING_FOUR_WHEEL_VEHICLE" 0 "RADAR_CLASS_UNKNOWN" ;
VAL_ 885 MovingState 3 "RADAR_MOVESTATE_STANDING" 2 "RADAR_MOVESTATE_STOPPED" 1 "RADAR_MOVESTATE_MOVING" 0 "RADAR_MOVESTATE_INDETERMINATE" ;
VAL_ 885 Class 4 "RADAR_CLASS_CONSTRUCTION_ELEMENT" 3 "RADAR_CLASS_MOVING_PEDESTRIAN" 2 "RADAR_CLASS_MOVING_TWO_WHEEL_VEHICLE" 1 "RADAR_CLASS_MOVING_FOUR_WHEEL_VEHICLE" 0 "RADAR_CLASS_UNKNOWN" ;
VAL_ 888 MovingState 3 "RADAR_MOVESTATE_STANDING" 2 "RADAR_MOVESTATE_STOPPED" 1 "RADAR_MOVESTATE_MOVING" 0 "RADAR_MOVESTATE_INDETERMINATE" ;
VAL_ 888 Class 4 "RADAR_CLASS_CONSTRUCTION_ELEMENT" 3 "RADAR_CLASS_MOVING_PEDESTRIAN" 2 "RADAR_CLASS_MOVING_TWO_WHEEL_VEHICLE" 1 "RADAR_CLASS_MOVING_FOUR_WHEEL_VEHICLE" 0 "RADAR_CLASS_UNKNOWN" ;
VAL_ 891 MovingState 3 "RADAR_MOVESTATE_STANDING" 2 "RADAR_MOVESTATE_STOPPED" 1 "RADAR_MOVESTATE_MOVING" 0 "RADAR_MOVESTATE_INDETERMINATE" ;
VAL_ 891 Class 4 "RADAR_CLASS_CONSTRUCTION_ELEMENT" 3 "RADAR_CLASS_MOVING_PEDESTRIAN" 2 "RADAR_CLASS_MOVING_TWO_WHEEL_VEHICLE" 1 "RADAR_CLASS_MOVING_FOUR_WHEEL_VEHICLE" 0 "RADAR_CLASS_UNKNOWN" ;
VAL_ 894 MovingState 3 "RADAR_MOVESTATE_STANDING" 2 "RADAR_MOVESTATE_STOPPED" 1 "RADAR_MOVESTATE_MOVING" 0 "RADAR_MOVESTATE_INDETERMINATE" ;
VAL_ 894 Class 4 "RADAR_CLASS_CONSTRUCTION_ELEMENT" 3 "RADAR_CLASS_MOVING_PEDESTRIAN" 2 "RADAR_CLASS_MOVING_TWO_WHEEL_VEHICLE" 1 "RADAR_CLASS_MOVING_FOUR_WHEEL_VEHICLE" 0 "RADAR_CLASS_UNKNOWN" ;
